AUTOSAR XML (schema 4-2-2)
package /STELLANTIS/EPT/ASWCs
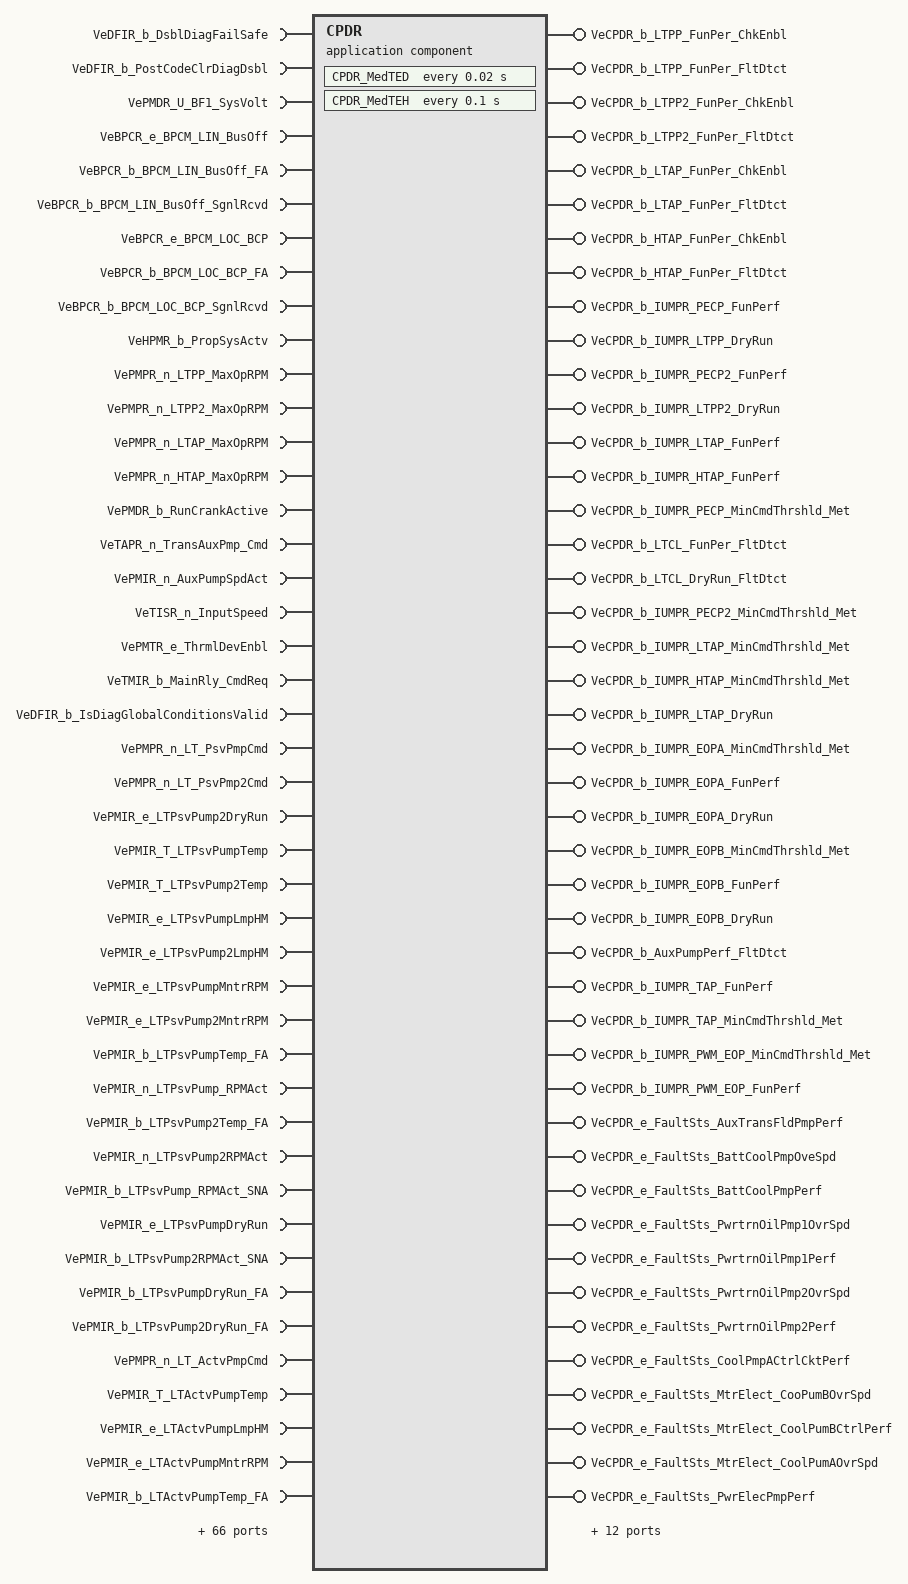
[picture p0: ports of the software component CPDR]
  application sw component type CPDR
    99 x require port:
      VeDFIR_b_DsblDiagFailSafe: variation-point={short-label=vpVeDFIR_b_DsblDiagFailSafe, sw-syscond=1}, nonqueued-receiver-com-spec{data-element=Value, init-value=0}, required-interface=VeDFIR_b_DsblDiagFailSafe
      VeDFIR_b_PostCodeClrDiagDsbl: variation-point={short-label=vpVeDFIR_b_PostCodeClrDiagDsbl, sw-syscond=1}, nonqueued-receiver-com-spec{data-element=Value, init-value=0}, required-interface=VeDFIR_b_PostCodeClrDiagDsbl
      VePMDR_U_BF1_SysVolt: variation-point={short-label=vpVePMDR_U_BF1_SysVolt, sw-syscond=1}, nonqueued-receiver-com-spec{data-element=Value, init-value=0}, required-interface=VePMDR_U_BF1_SysVolt
      VeBPCR_e_BPCM_LIN_BusOff: variation-point={short-label=vpVeBPCR_e_BPCM_LIN_BusOff, sw-syscond=1}, nonqueued-receiver-com-spec{data-element=Value, init-value=CeBPCR_e_LIN_BusOff_Disabled}, required-interface=VeBPCR_e_BPCM_LIN_BusOff
      VeBPCR_b_BPCM_LIN_BusOff_FA: variation-point={short-label=vpVeBPCR_b_BPCM_LIN_BusOff_FA, sw-syscond=1}, nonqueued-receiver-com-spec{data-element=Value, init-value=0}, required-interface=VeBPCR_b_BPCM_LIN_BusOff_FA
      VeBPCR_b_BPCM_LIN_BusOff_SgnlRcvd: variation-point={short-label=vpVeBPCR_b_BPCM_LIN_BusOff_SgnlRcvd, sw-syscond=1}, nonqueued-receiver-com-spec{data-element=Value, init-value=0}, required-interface=VeBPCR_b_BPCM_LIN_BusOff_SgnlRcvd
      VeBPCR_e_BPCM_LOC_BCP: variation-point={short-label=vpVeBPCR_e_BPCM_LOC_BCP, sw-syscond=1}, nonqueued-receiver-com-spec{data-element=Value, init-value=CeBPCR_e_LOC_BCP_False}, required-interface=VeBPCR_e_BPCM_LOC_BCP
      VeBPCR_b_BPCM_LOC_BCP_FA: variation-point={short-label=vpVeBPCR_b_BPCM_LOC_BCP_FA, sw-syscond=1}, nonqueued-receiver-com-spec{data-element=Value, init-value=0}, required-interface=VeBPCR_b_BPCM_LOC_BCP_FA
      VeBPCR_b_BPCM_LOC_BCP_SgnlRcvd: variation-point={short-label=vpVeBPCR_b_BPCM_LOC_BCP_SgnlRcvd, sw-syscond=1}, nonqueued-receiver-com-spec{data-element=Value, init-value=0}, required-interface=VeBPCR_b_BPCM_LOC_BCP_SgnlRcvd
      VeHPMR_b_PropSysActv: variation-point={short-label=vpVeHPMR_b_PropSysActv, sw-syscond=1}, nonqueued-receiver-com-spec{data-element=Value, init-value=0}, required-interface=VeHPMR_b_PropSysActv
      VePMPR_n_LTPP_MaxOpRPM: variation-point={short-label=vpVePMPR_n_LTPP_MaxOpRPM, sw-syscond=1}, nonqueued-receiver-com-spec{data-element=Value, init-value=0}, required-interface=VePMPR_n_LTPP_MaxOpRPM
      VePMPR_n_LTPP2_MaxOpRPM: variation-point={short-label=vpVePMPR_n_LTPP2_MaxOpRPM, sw-syscond=1}, nonqueued-receiver-com-spec{data-element=Value, init-value=0}, required-interface=VePMPR_n_LTPP2_MaxOpRPM
      VePMPR_n_LTAP_MaxOpRPM: variation-point={short-label=vpVePMPR_n_LTAP_MaxOpRPM, sw-syscond=1}, nonqueued-receiver-com-spec{data-element=Value, init-value=0}, required-interface=VePMPR_n_LTAP_MaxOpRPM
      VePMPR_n_HTAP_MaxOpRPM: variation-point={short-label=vpVePMPR_n_HTAP_MaxOpRPM, sw-syscond=1}, nonqueued-receiver-com-spec{data-element=Value, init-value=0}, required-interface=VePMPR_n_HTAP_MaxOpRPM
      VePMDR_b_RunCrankActive: variation-point={short-label=vpVePMDR_b_RunCrankActive, sw-syscond=1}, nonqueued-receiver-com-spec{data-element=Value, init-value=0}, required-interface=VePMDR_b_RunCrankActive
      VeTAPR_n_TransAuxPmp_Cmd: variation-point={short-label=vpVeTAPR_n_TransAuxPmp_Cmd, sw-syscond=1}, nonqueued-receiver-com-spec{data-element=Value, init-value=0}, required-interface=VeTAPR_n_TransAuxPmp_Cmd
      VePMIR_n_AuxPumpSpdAct: variation-point={short-label=vpVePMIR_n_AuxPumpSpdAct, sw-syscond=1}, nonqueued-receiver-com-spec{data-element=Value, init-value=0}, required-interface=VePMIR_n_AuxPumpSpdAct
      VeTISR_n_InputSpeed: variation-point={short-label=vpVeTISR_n_InputSpeed, sw-syscond=1}, nonqueued-receiver-com-spec{data-element=Value, init-value=0}, required-interface=VeTISR_n_InputSpeed
      VePMTR_e_ThrmlDevEnbl: variation-point={short-label=vpVePMTR_e_ThrmlDevEnbl, sw-syscond=1}, nonqueued-receiver-com-spec{data-element=Value, init-value=CePMTR_e_DISBL_All_Thrml}, required-interface=VePMTR_e_ThrmlDevEnbl
      VeTMIR_b_MainRly_CmdReq: variation-point={short-label=vpVeTMIR_b_MainRly_CmdReq, sw-syscond=1}, nonqueued-receiver-com-spec{data-element=Value, init-value=0}, required-interface=VeTMIR_b_MainRly_CmdReq
      VeDFIR_b_IsDiagGlobalConditionsValid: variation-point={short-label=vpVeDFIR_b_IsDiagGlobalConditionsValid, sw-syscond=1}, nonqueued-receiver-com-spec{data-element=Value, init-value=0}, required-interface=VeDFIR_b_IsDiagGlobalConditionsValid
      VePMPR_n_LT_PsvPmpCmd: variation-point={short-label=vpVePMPR_n_LT_PsvPmpCmd, sw-syscond=1}, nonqueued-receiver-com-spec{data-element=Value, init-value=0}, required-interface=VePMPR_n_LT_PsvPmpCmd
      VePMPR_n_LT_PsvPmp2Cmd: variation-point={short-label=vpVePMPR_n_LT_PsvPmp2Cmd, sw-syscond=1}, nonqueued-receiver-com-spec{data-element=Value, init-value=0}, required-interface=VePMPR_n_LT_PsvPmp2Cmd
      VePMIR_e_LTPsvPump2DryRun: variation-point={short-label=vpVePMIR_e_LTPsvPump2DryRun, sw-syscond=1}, nonqueued-receiver-com-spec{data-element=Value, init-value=CePMPR_e_FTSNA_False}, required-interface=VePMIR_e_LTPsvPump2DryRun
      VePMIR_T_LTPsvPumpTemp: variation-point={short-label=vpVePMIR_T_LTPsvPumpTemp, sw-syscond=1}, nonqueued-receiver-com-spec{data-element=Value, init-value=0}, required-interface=VePMIR_T_LTPsvPumpTemp
      VePMIR_T_LTPsvPump2Temp: variation-point={short-label=vpVePMIR_T_LTPsvPump2Temp, sw-syscond=1}, nonqueued-receiver-com-spec{data-element=Value, init-value=0}, required-interface=VePMIR_T_LTPsvPump2Temp
      VePMIR_e_LTPsvPumpLmpHM: variation-point={short-label=vpVePMIR_e_LTPsvPumpLmpHM, sw-syscond=1}, nonqueued-receiver-com-spec{data-element=Value, init-value=CePMPR_e_FTSNA_False}, required-interface=VePMIR_e_LTPsvPumpLmpHM
      VePMIR_e_LTPsvPump2LmpHM: variation-point={short-label=vpVePMIR_e_LTPsvPump2LmpHM, sw-syscond=1}, nonqueued-receiver-com-spec{data-element=Value, init-value=CePMPR_e_FTSNA_False}, required-interface=VePMIR_e_LTPsvPump2LmpHM
      VePMIR_e_LTPsvPumpMntrRPM: variation-point={short-label=vpVePMIR_e_LTPsvPumpMntrRPM, sw-syscond=1}, nonqueued-receiver-com-spec{data-element=Value, init-value=CePMPR_e_TFSNA_False}, required-interface=VePMIR_e_LTPsvPumpMntrRPM
      VePMIR_e_LTPsvPump2MntrRPM: variation-point={short-label=vpVePMIR_e_LTPsvPump2MntrRPM, sw-syscond=1}, nonqueued-receiver-com-spec{data-element=Value, init-value=CePMPR_e_TFSNA_False}, required-interface=VePMIR_e_LTPsvPump2MntrRPM
      VePMIR_b_LTPsvPumpTemp_FA: variation-point={short-label=vpVePMIR_b_LTPsvPumpTemp_FA, sw-syscond=1}, nonqueued-receiver-com-spec{data-element=Value, init-value=0}, required-interface=VePMIR_b_LTPsvPumpTemp_FA
      VePMIR_n_LTPsvPump_RPMAct: variation-point={short-label=vpVePMIR_n_LTPsvPump_RPMAct, sw-syscond=1}, nonqueued-receiver-com-spec{data-element=Value, init-value=0}, required-interface=VePMIR_n_LTPsvPump_RPMAct
      VePMIR_b_LTPsvPump2Temp_FA: variation-point={short-label=vpVePMIR_b_LTPsvPump2Temp_FA, sw-syscond=1}, nonqueued-receiver-com-spec{data-element=Value, init-value=0}, required-interface=VePMIR_b_LTPsvPump2Temp_FA
      VePMIR_n_LTPsvPump2RPMAct: variation-point={short-label=vpVePMIR_n_LTPsvPump2RPMAct, sw-syscond=1}, nonqueued-receiver-com-spec{data-element=Value, init-value=0}, required-interface=VePMIR_n_LTPsvPump2RPMAct
      VePMIR_b_LTPsvPump_RPMAct_SNA: variation-point={short-label=vpVePMIR_b_LTPsvPump_RPMAct_SNA, sw-syscond=1}, nonqueued-receiver-com-spec{data-element=Value, init-value=0}, required-interface=VePMIR_b_LTPsvPump_RPMAct_SNA
      VePMIR_e_LTPsvPumpDryRun: variation-point={short-label=vpVePMIR_e_LTPsvPumpDryRun, sw-syscond=1}, nonqueued-receiver-com-spec{data-element=Value, init-value=CePMPR_e_FTSNA_False}, required-interface=VePMIR_e_LTPsvPumpDryRun
      VePMIR_b_LTPsvPump2RPMAct_SNA: variation-point={short-label=vpVePMIR_b_LTPsvPump2RPMAct_SNA, sw-syscond=1}, nonqueued-receiver-com-spec{data-element=Value, init-value=0}, required-interface=VePMIR_b_LTPsvPump2RPMAct_SNA
      VePMIR_b_LTPsvPumpDryRun_FA: variation-point={short-label=vpVePMIR_b_LTPsvPumpDryRun_FA, sw-syscond=1}, nonqueued-receiver-com-spec{data-element=Value, init-value=0}, required-interface=VePMIR_b_LTPsvPumpDryRun_FA
      VePMIR_b_LTPsvPump2DryRun_FA: variation-point={short-label=vpVePMIR_b_LTPsvPump2DryRun_FA, sw-syscond=1}, nonqueued-receiver-com-spec{data-element=Value, init-value=0}, required-interface=VePMIR_b_LTPsvPump2DryRun_FA
      VePMPR_n_LT_ActvPmpCmd: variation-point={short-label=vpVePMPR_n_LT_ActvPmpCmd, sw-syscond=1}, nonqueued-receiver-com-spec{data-element=Value, init-value=0}, required-interface=VePMPR_n_LT_ActvPmpCmd
      VePMIR_T_LTActvPumpTemp: variation-point={short-label=vpVePMIR_T_LTActvPumpTemp, sw-syscond=1}, nonqueued-receiver-com-spec{data-element=Value, init-value=0}, required-interface=VePMIR_T_LTActvPumpTemp
      VePMIR_e_LTActvPumpLmpHM: variation-point={short-label=vpVePMIR_e_LTActvPumpLmpHM, sw-syscond=1}, nonqueued-receiver-com-spec{data-element=Value, init-value=CePMPR_e_FTSNA_False}, required-interface=VePMIR_e_LTActvPumpLmpHM
      VePMIR_e_LTActvPumpMntrRPM: variation-point={short-label=vpVePMIR_e_LTActvPumpMntrRPM, sw-syscond=1}, nonqueued-receiver-com-spec{data-element=Value, init-value=CePMPR_e_FTSNA_False}, required-interface=VePMIR_e_LTActvPumpMntrRPM
      VePMIR_b_LTActvPumpTemp_FA: variation-point={short-label=vpVePMIR_b_LTActvPumpTemp_FA, sw-syscond=1}, nonqueued-receiver-com-spec{data-element=Value, init-value=0}, required-interface=VePMIR_b_LTActvPumpTemp_FA
      VePMIR_n_LTActvPumpRPMAct: variation-point={short-label=vpVePMIR_n_LTActvPumpRPMAct, sw-syscond=1}, nonqueued-receiver-com-spec{data-element=Value, init-value=0}, required-interface=VePMIR_n_LTActvPumpRPMAct
      VePMIR_b_LTActvPumpRPMAct_SNA: variation-point={short-label=vpVePMIR_b_LTActvPumpRPMAct_SNA, sw-syscond=1}, nonqueued-receiver-com-spec{data-element=Value, init-value=0}, required-interface=VePMIR_b_LTActvPumpRPMAct_SNA
      VePMIR_b_LTActvPumpDryRun_SNA: variation-point={short-label=vpVePMIR_b_LTActvPumpDryRun_SNA, sw-syscond=1}, nonqueued-receiver-com-spec{data-element=Value, init-value=0}, required-interface=VePMIR_b_LTActvPumpDryRun_SNA
      VePMIR_e_LTActvPumpDryRun: variation-point={short-label=vpVePMIR_e_LTActvPumpDryRun, sw-syscond=1}, nonqueued-receiver-com-spec{data-element=Value, init-value=CePMPR_e_FTSNA_False}, required-interface=VePMIR_e_LTActvPumpDryRun
      VePMIR_b_LTActvPumpDryRun_FA: variation-point={short-label=vpVePMIR_b_LTActvPumpDryRun_FA, sw-syscond=1}, nonqueued-receiver-com-spec{data-element=Value, init-value=0}, required-interface=VePMIR_b_LTActvPumpDryRun_FA
      VePMIR_e_HTAuxPumpDryRun: variation-point={short-label=vpVePMIR_e_HTAuxPumpDryRun, sw-syscond=1}, nonqueued-receiver-com-spec{data-element=Value, init-value=CePMPR_e_FTSNA_False}, required-interface=VePMIR_e_HTAuxPumpDryRun
      VePMIR_n_HTAuxPumpRPMAct: variation-point={short-label=vpVePMIR_n_HTAuxPumpRPMAct, sw-syscond=1}, nonqueued-receiver-com-spec{data-element=Value, init-value=0}, required-interface=VePMIR_n_HTAuxPumpRPMAct
      VePMIR_b_HTAuxPumpRPMAct_SNA: variation-point={short-label=vpVePMIR_b_HTAuxPumpRPMAct_SNA, sw-syscond=1}, nonqueued-receiver-com-spec{data-element=Value, init-value=0}, required-interface=VePMIR_b_HTAuxPumpRPMAct_SNA
      VePMPR_n_HT_AuxPmpCmd: variation-point={short-label=vpVePMPR_n_HT_AuxPmpCmd, sw-syscond=1}, nonqueued-receiver-com-spec{data-element=Value, init-value=0}, required-interface=VePMPR_n_HT_AuxPmpCmd
      VePMIR_T_HTAuxPumpTemp: variation-point={short-label=vpVePMIR_T_HTAuxPumpTemp, sw-syscond=1}, nonqueued-receiver-com-spec{data-element=Value, init-value=0}, required-interface=VePMIR_T_HTAuxPumpTemp
      VePMIR_e_HTAuxPumpLmpHM: variation-point={short-label=vpVePMIR_e_HTAuxPumpLmpHM, sw-syscond=1}, nonqueued-receiver-com-spec{data-element=Value, init-value=CePMPR_e_FTSNA_False}, required-interface=VePMIR_e_HTAuxPumpLmpHM
      VePMIR_e_HTAuxPumpMntrRPM: variation-point={short-label=vpVePMIR_e_HTAuxPumpMntrRPM, sw-syscond=1}, nonqueued-receiver-com-spec{data-element=Value, init-value=CePMPR_e_TFSNA_False}, required-interface=VePMIR_e_HTAuxPumpMntrRPM
      VePMIR_b_HTAuxPumpTemp_FA: variation-point={short-label=vpVePMIR_b_HTAuxPumpTemp_FA, sw-syscond=1}, nonqueued-receiver-com-spec{data-element=Value, init-value=0}, required-interface=VePMIR_b_HTAuxPumpTemp_FA
      VePMIR_b_AuxPumpSpdAct_SNA: variation-point={short-label=vpVePMIR_b_AuxPumpSpdAct_SNA, sw-syscond=1}, nonqueued-receiver-com-spec{data-element=Value, init-value=0}, required-interface=VePMIR_b_AuxPumpSpdAct_SNA
      VePMIR_T_TransAuxPumpOilTemp: variation-point={short-label=vpVePMIR_T_TransAuxPumpOilTemp, sw-syscond=1}, nonqueued-receiver-com-spec{data-element=Value, init-value=0}, required-interface=VePMIR_T_TransAuxPumpOilTemp
      VePMIR_b_TransAuxPumpOilTemp_FA: variation-point={short-label=vpVePMIR_b_TransAuxPumpOilTemp_FA, sw-syscond=1}, nonqueued-receiver-com-spec{data-element=Value, init-value=0}, required-interface=VePMIR_b_TransAuxPumpOilTemp_FA
      VePMIR_b_TransAuxPumpDryRun_FA: variation-point={short-label=vpVePMIR_b_TransAuxPumpDryRun_FA, sw-syscond=1}, nonqueued-receiver-com-spec{data-element=Value, init-value=0}, required-interface=VePMIR_b_TransAuxPumpDryRun_FA
      VePMIR_b_AuxPumpSpdAct_FA: variation-point={short-label=vpVePMIR_b_AuxPumpSpdAct_FA, sw-syscond=1}, nonqueued-receiver-com-spec{data-element=Value, init-value=0}, required-interface=VePMIR_b_AuxPumpSpdAct_FA
      VePMIR_e_TransAuxPumpDryRun: variation-point={short-label=vpVePMIR_e_TransAuxPumpDryRun, sw-syscond=1}, nonqueued-receiver-com-spec{data-element=Value, init-value=CeTAPR_e_TAP_FalseTrueSNA_False}, required-interface=VePMIR_e_TransAuxPumpDryRun
      VeTAPR_n_TransAuxPmp2_Cmd: variation-point={short-label=vpVeTAPR_n_TransAuxPmp2_Cmd, sw-syscond=1}, nonqueued-receiver-com-spec{data-element=Value, init-value=0}, required-interface=VeTAPR_n_TransAuxPmp2_Cmd
      VePMIR_n_TransAuxPump2SpdAct: variation-point={short-label=vpVePMIR_n_TransAuxPump2SpdAct, sw-syscond=1}, nonqueued-receiver-com-spec{data-element=Value, init-value=0}, required-interface=VePMIR_n_TransAuxPump2SpdAct
      VePMIR_b_TransAuxPump2SpdAct_SNA: variation-point={short-label=vpVePMIR_b_TransAuxPump2SpdAct_SNA, sw-syscond=1}, nonqueued-receiver-com-spec{data-element=Value, init-value=0}, required-interface=VePMIR_b_TransAuxPump2SpdAct_SNA
      VePMIR_T_TransAuxPump2OilTemp: variation-point={short-label=vpVePMIR_T_TransAuxPump2OilTemp, sw-syscond=1}, nonqueued-receiver-com-spec{data-element=Value, init-value=0}, required-interface=VePMIR_T_TransAuxPump2OilTemp
      VePMIR_b_TransAuxPump2OilTemp_FA: variation-point={short-label=vpVePMIR_b_TransAuxPump2OilTemp_FA, sw-syscond=1}, nonqueued-receiver-com-spec{data-element=Value, init-value=0}, required-interface=VePMIR_b_TransAuxPump2OilTemp_FA
      VePMIR_b_TransAuxPump2DryRun_FA: variation-point={short-label=vpVePMIR_b_TransAuxPump2DryRun_FA, sw-syscond=1}, nonqueued-receiver-com-spec{data-element=Value, init-value=0}, required-interface=VePMIR_b_TransAuxPump2DryRun_FA
      VePMIR_b_TransAuxPump2SpdAct_FA: variation-point={short-label=vpVePMIR_b_TransAuxPump2SpdAct_FA, sw-syscond=1}, nonqueued-receiver-com-spec{data-element=Value, init-value=0}, required-interface=VePMIR_b_TransAuxPump2SpdAct_FA
      VePMIR_e_TransAuxPump2DryRun: variation-point={short-label=vpVePMIR_e_TransAuxPump2DryRun, sw-syscond=1}, nonqueued-receiver-com-spec{data-element=Value, init-value=CeTAPR_e_TAP_FalseTrueSNA_False}, required-interface=VePMIR_e_TransAuxPump2DryRun
      VeDMAB_y_StatusByte_LIN1_BusOff: nonqueued-receiver-com-spec{data-element=Value, init-value=0}, required-interface=VeDMAB_y_StatusByte_LIN1_BusOff
      VeDMAB_y_StatusByte_LostCommTAP: nonqueued-receiver-com-spec{data-element=Value, init-value=0}, required-interface=VeDMAB_y_StatusByte_LostCommTAP
      VeDMAB_y_StatusByte_ThrmlRlyCtrlCkt: nonqueued-receiver-com-spec{data-element=Value, init-value=0}, required-interface=VeDMAB_y_StatusByte_ThrmlRlyCtrlCkt
      VeDMAB_y_StatusByte_LostCommHB_CoolPmp: nonqueued-receiver-com-spec{data-element=Value, init-value=0}, required-interface=VeDMAB_y_StatusByte_LostCommHB_CoolPmp
      VeDMAB_y_StatusByte_CommBus_B_Off: nonqueued-receiver-com-spec{data-element=Value, init-value=0}, required-interface=VeDMAB_y_StatusByte_CommBus_B_Off
      VeDMAB_y_StatusByte_InvData_BECM_CANC11: nonqueued-receiver-com-spec{data-element=Value, init-value=0}, required-interface=VeDMAB_y_StatusByte_InvData_BECM_CANC11
      VeDMAB_y_StatusByte_LosCommBECM_A_CANC11: nonqueued-receiver-com-spec{data-element=Value, init-value=0}, required-interface=VeDMAB_y_StatusByte_LosCommBECM_A_CANC11
      VeDMAB_y_StatusByte_CommBusOff: nonqueued-receiver-com-spec{data-element=Value, init-value=0}, required-interface=VeDMAB_y_StatusByte_CommBusOff
      VeDMAB_y_StatusByte_InvData_BECM: nonqueued-receiver-com-spec{data-element=Value, init-value=0}, required-interface=VeDMAB_y_StatusByte_InvData_BECM
      VeDMAB_y_StatusByte_LosCommBECM_A: nonqueued-receiver-com-spec{data-element=Value, init-value=0}, required-interface=VeDMAB_y_StatusByte_LosCommBECM_A
      VeDMAB_y_StatusByte_BattCoolPmpPerf: nonqueued-receiver-com-spec{data-element=Value, init-value=0}, required-interface=VeDMAB_y_StatusByte_BattCoolPmpPerf
      VeDMAB_y_StatusByte_BattCoolPmpOveSpd: nonqueued-receiver-com-spec{data-element=Value, init-value=0}, required-interface=VeDMAB_y_StatusByte_BattCoolPmpOveSpd
      VeDMAB_y_StatusByte_LostCommPwrtrn_OilPmp1: nonqueued-receiver-com-spec{data-element=Value, init-value=0}, required-interface=VeDMAB_y_StatusByte_LostCommPwrtrn_OilPmp1
      VeDMAB_y_StatusByte_PwrtrnOilPmp1OvrSpd: nonqueued-receiver-com-spec{data-element=Value, init-value=0}, required-interface=VeDMAB_y_StatusByte_PwrtrnOilPmp1OvrSpd
      VeDMAB_y_StatusByte_PwrtrnOilPmp1Perf: nonqueued-receiver-com-spec{data-element=Value, init-value=0}, required-interface=VeDMAB_y_StatusByte_PwrtrnOilPmp1Perf
      VeDMAB_y_StatusByte_LIN3_BusOff: nonqueued-receiver-com-spec{data-element=Value, init-value=0}, required-interface=VeDMAB_y_StatusByte_LIN3_BusOff
      VeDMAB_y_StatusByte_LostCommPwrtrn_OilPmp2: nonqueued-receiver-com-spec{data-element=Value, init-value=0}, required-interface=VeDMAB_y_StatusByte_LostCommPwrtrn_OilPmp2
      VeDMAB_y_StatusByte_PwrtrnOilPmp2OvrSpd: nonqueued-receiver-com-spec{data-element=Value, init-value=0}, required-interface=VeDMAB_y_StatusByte_PwrtrnOilPmp2OvrSpd
      VeDMAB_y_StatusByte_PwrtrnOilPmp2Perf: nonqueued-receiver-com-spec{data-element=Value, init-value=0}, required-interface=VeDMAB_y_StatusByte_PwrtrnOilPmp2Perf
      VeDMAB_y_StatusByte_LIN2_BusOff: nonqueued-receiver-com-spec{data-element=Value, init-value=0}, required-interface=VeDMAB_y_StatusByte_LIN2_BusOff
      VeDMAB_y_StatusByte_LostCommCoolPmpA: nonqueued-receiver-com-spec{data-element=Value, init-value=0}, required-interface=VeDMAB_y_StatusByte_LostCommCoolPmpA
      VeDMAB_y_StatusByte_CoolPmpACtrlCktPerf: nonqueued-receiver-com-spec{data-element=Value, init-value=0}, required-interface=VeDMAB_y_StatusByte_CoolPmpACtrlCktPerf
      VeDMAB_y_StatusByte_LostCommMtrElectCoolPmpB: nonqueued-receiver-com-spec{data-element=Value, init-value=0}, required-interface=VeDMAB_y_StatusByte_LostCommMtrElectCoolPmpB
      VeDMAB_y_StatusByte_MtrElect_CoolPumBCtrlPerf: nonqueued-receiver-com-spec{data-element=Value, init-value=0}, required-interface=VeDMAB_y_StatusByte_MtrElect_CoolPumBCtrlPerf
      VeDMAB_y_StatusByte_LostCommMtrElectCoolPmpA: nonqueued-receiver-com-spec{data-element=Value, init-value=0}, required-interface=VeDMAB_y_StatusByte_LostCommMtrElectCoolPmpA
      VeDMAB_y_StatusByte_MtrElect_CoolPumAOvrSpd: nonqueued-receiver-com-spec{data-element=Value, init-value=0}, required-interface=VeDMAB_y_StatusByte_MtrElect_CoolPumAOvrSpd
      VeDMAB_y_StatusByte_PwrElecPmpPerf: nonqueued-receiver-com-spec{data-element=Value, init-value=0}, required-interface=VeDMAB_y_StatusByte_PwrElecPmpPerf
      VeDMAB_y_StatusByte_MtrElect_CooPumBOvrSpd: nonqueued-receiver-com-spec{data-element=Value, init-value=0}, required-interface=VeDMAB_y_StatusByte_MtrElect_CooPumBOvrSpd
    45 x provide port:
      VeCPDR_b_LTPP_FunPer_ChkEnbl: nonqueued-sender-com-spec{data-element=Value, init-value=0}, provided-interface=VeCPDR_b_LTPP_FunPer_ChkEnbl
      VeCPDR_b_LTPP_FunPer_FltDtct: nonqueued-sender-com-spec{data-element=Value, init-value=0}, provided-interface=VeCPDR_b_LTPP_FunPer_FltDtct
      VeCPDR_b_LTPP2_FunPer_ChkEnbl: nonqueued-sender-com-spec{data-element=Value, init-value=0}, provided-interface=VeCPDR_b_LTPP2_FunPer_ChkEnbl
      VeCPDR_b_LTPP2_FunPer_FltDtct: nonqueued-sender-com-spec{data-element=Value, init-value=0}, provided-interface=VeCPDR_b_LTPP2_FunPer_FltDtct
      VeCPDR_b_LTAP_FunPer_ChkEnbl: nonqueued-sender-com-spec{data-element=Value, init-value=0}, provided-interface=VeCPDR_b_LTAP_FunPer_ChkEnbl
      VeCPDR_b_LTAP_FunPer_FltDtct: nonqueued-sender-com-spec{data-element=Value, init-value=0}, provided-interface=VeCPDR_b_LTAP_FunPer_FltDtct
      VeCPDR_b_HTAP_FunPer_ChkEnbl: nonqueued-sender-com-spec{data-element=Value, init-value=0}, provided-interface=VeCPDR_b_HTAP_FunPer_ChkEnbl
      VeCPDR_b_HTAP_FunPer_FltDtct: nonqueued-sender-com-spec{data-element=Value, init-value=0}, provided-interface=VeCPDR_b_HTAP_FunPer_FltDtct
      VeCPDR_b_IUMPR_PECP_FunPerf: nonqueued-sender-com-spec{data-element=Value, init-value=0}, provided-interface=VeCPDR_b_IUMPR_PECP_FunPerf
      VeCPDR_b_IUMPR_LTPP_DryRun: nonqueued-sender-com-spec{data-element=Value, init-value=0}, provided-interface=VeCPDR_b_IUMPR_LTPP_DryRun
      VeCPDR_b_IUMPR_PECP2_FunPerf: nonqueued-sender-com-spec{data-element=Value, init-value=0}, provided-interface=VeCPDR_b_IUMPR_PECP2_FunPerf
      VeCPDR_b_IUMPR_LTPP2_DryRun: nonqueued-sender-com-spec{data-element=Value, init-value=0}, provided-interface=VeCPDR_b_IUMPR_LTPP2_DryRun
      VeCPDR_b_IUMPR_LTAP_FunPerf: nonqueued-sender-com-spec{data-element=Value, init-value=0}, provided-interface=VeCPDR_b_IUMPR_LTAP_FunPerf
      VeCPDR_b_IUMPR_HTAP_FunPerf: nonqueued-sender-com-spec{data-element=Value, init-value=0}, provided-interface=VeCPDR_b_IUMPR_HTAP_FunPerf
      VeCPDR_b_IUMPR_PECP_MinCmdThrshld_Met: nonqueued-sender-com-spec{data-element=Value, init-value=0}, provided-interface=VeCPDR_b_IUMPR_PECP_MinCmdThrshld_Met
      VeCPDR_b_LTCL_FunPer_FltDtct: nonqueued-sender-com-spec{data-element=Value, init-value=0}, provided-interface=VeCPDR_b_LTCL_FunPer_FltDtct
      VeCPDR_b_LTCL_DryRun_FltDtct: nonqueued-sender-com-spec{data-element=Value, init-value=0}, provided-interface=VeCPDR_b_LTCL_DryRun_FltDtct
      VeCPDR_b_IUMPR_PECP2_MinCmdThrshld_Met: nonqueued-sender-com-spec{data-element=Value, init-value=0}, provided-interface=VeCPDR_b_IUMPR_PECP2_MinCmdThrshld_Met
      VeCPDR_b_IUMPR_LTAP_MinCmdThrshld_Met: nonqueued-sender-com-spec{data-element=Value, init-value=0}, provided-interface=VeCPDR_b_IUMPR_LTAP_MinCmdThrshld_Met
      VeCPDR_b_IUMPR_HTAP_MinCmdThrshld_Met: nonqueued-sender-com-spec{data-element=Value, init-value=0}, provided-interface=VeCPDR_b_IUMPR_HTAP_MinCmdThrshld_Met
      VeCPDR_b_IUMPR_LTAP_DryRun: nonqueued-sender-com-spec{data-element=Value, init-value=0}, provided-interface=VeCPDR_b_IUMPR_LTAP_DryRun
      VeCPDR_b_IUMPR_EOPA_MinCmdThrshld_Met: nonqueued-sender-com-spec{data-element=Value, init-value=0}, provided-interface=VeCPDR_b_IUMPR_EOPA_MinCmdThrshld_Met
      VeCPDR_b_IUMPR_EOPA_FunPerf: nonqueued-sender-com-spec{data-element=Value, init-value=0}, provided-interface=VeCPDR_b_IUMPR_EOPA_FunPerf
      VeCPDR_b_IUMPR_EOPA_DryRun: nonqueued-sender-com-spec{data-element=Value, init-value=0}, provided-interface=VeCPDR_b_IUMPR_EOPA_DryRun
      VeCPDR_b_IUMPR_EOPB_MinCmdThrshld_Met: nonqueued-sender-com-spec{data-element=Value, init-value=0}, provided-interface=VeCPDR_b_IUMPR_EOPB_MinCmdThrshld_Met
      VeCPDR_b_IUMPR_EOPB_FunPerf: nonqueued-sender-com-spec{data-element=Value, init-value=0}, provided-interface=VeCPDR_b_IUMPR_EOPB_FunPerf
      VeCPDR_b_IUMPR_EOPB_DryRun: nonqueued-sender-com-spec{data-element=Value, init-value=0}, provided-interface=VeCPDR_b_IUMPR_EOPB_DryRun
      VeCPDR_b_AuxPumpPerf_FltDtct: nonqueued-sender-com-spec{data-element=Value, init-value=0}, provided-interface=VeCPDR_b_AuxPumpPerf_FltDtct
      VeCPDR_b_IUMPR_TAP_FunPerf: nonqueued-sender-com-spec{data-element=Value, init-value=0}, provided-interface=VeCPDR_b_IUMPR_TAP_FunPerf
      VeCPDR_b_IUMPR_TAP_MinCmdThrshld_Met: nonqueued-sender-com-spec{data-element=Value, init-value=0}, provided-interface=VeCPDR_b_IUMPR_TAP_MinCmdThrshld_Met
      VeCPDR_b_IUMPR_PWM_EOP_MinCmdThrshld_Met: nonqueued-sender-com-spec{data-element=Value, init-value=0}, provided-interface=VeCPDR_b_IUMPR_PWM_EOP_MinCmdThrshld_Met
      VeCPDR_b_IUMPR_PWM_EOP_FunPerf: nonqueued-sender-com-spec{data-element=Value, init-value=0}, provided-interface=VeCPDR_b_IUMPR_PWM_EOP_FunPerf
      VeCPDR_e_FaultSts_AuxTransFldPmpPerf: nonqueued-sender-com-spec{data-element=Value, init-value=CeDFIB_e_Init}, provided-interface=VeCPDR_e_FaultSts_AuxTransFldPmpPerf
      VeCPDR_e_FaultSts_BattCoolPmpOveSpd: nonqueued-sender-com-spec{data-element=Value, init-value=CeDFIB_e_Init}, provided-interface=VeCPDR_e_FaultSts_BattCoolPmpOveSpd
      VeCPDR_e_FaultSts_BattCoolPmpPerf: nonqueued-sender-com-spec{data-element=Value, init-value=CeDFIB_e_Init}, provided-interface=VeCPDR_e_FaultSts_BattCoolPmpPerf
      VeCPDR_e_FaultSts_PwrtrnOilPmp1OvrSpd: nonqueued-sender-com-spec{data-element=Value, init-value=CeDFIB_e_Init}, provided-interface=VeCPDR_e_FaultSts_PwrtrnOilPmp1OvrSpd
      VeCPDR_e_FaultSts_PwrtrnOilPmp1Perf: nonqueued-sender-com-spec{data-element=Value, init-value=CeDFIB_e_Init}, provided-interface=VeCPDR_e_FaultSts_PwrtrnOilPmp1Perf
      VeCPDR_e_FaultSts_PwrtrnOilPmp2OvrSpd: nonqueued-sender-com-spec{data-element=Value, init-value=CeDFIB_e_Init}, provided-interface=VeCPDR_e_FaultSts_PwrtrnOilPmp2OvrSpd
      VeCPDR_e_FaultSts_PwrtrnOilPmp2Perf: nonqueued-sender-com-spec{data-element=Value, init-value=CeDFIB_e_Init}, provided-interface=VeCPDR_e_FaultSts_PwrtrnOilPmp2Perf
      VeCPDR_e_FaultSts_CoolPmpACtrlCktPerf: nonqueued-sender-com-spec{data-element=Value, init-value=CeDFIB_e_Init}, provided-interface=VeCPDR_e_FaultSts_CoolPmpACtrlCktPerf
      VeCPDR_e_FaultSts_MtrElect_CooPumBOvrSpd: nonqueued-sender-com-spec{data-element=Value, init-value=CeDFIB_e_Init}, provided-interface=VeCPDR_e_FaultSts_MtrElect_CooPumBOvrSpd
      VeCPDR_e_FaultSts_MtrElect_CoolPumBCtrlPerf: nonqueued-sender-com-spec{data-element=Value, init-value=CeDFIB_e_Init}, provided-interface=VeCPDR_e_FaultSts_MtrElect_CoolPumBCtrlPerf
      VeCPDR_e_FaultSts_MtrElect_CoolPumAOvrSpd: nonqueued-sender-com-spec{data-element=Value, init-value=CeDFIB_e_Init}, provided-interface=VeCPDR_e_FaultSts_MtrElect_CoolPumAOvrSpd
      VeCPDR_e_FaultSts_PwrElecPmpPerf: nonqueued-sender-com-spec{data-element=Value, init-value=CeDFIB_e_Init}, provided-interface=VeCPDR_e_FaultSts_PwrElecPmpPerf
      VeCPDR_e_FaultSts_Aux_TF_Pmp_CM_Fdbck_SigRan: nonqueued-sender-com-spec{data-element=Value, init-value=CeDFIB_e_Init}, provided-interface=VeCPDR_e_FaultSts_Aux_TF_Pmp_CM_Fdbck_SigRan
    11 x require port:
      NeCPDR_Cnt_EOPA_FunDryRun_MFOP_Rx: nv-require-com-spec{init-value=0, variable=NeCPDR_Cnt_EOPA_FunDryRun_MFOP}, required-interface=NeCPDR_Cnt_EOPA_FunDryRun_MFOP
      NeCPDR_Cnt_EOPA_FunPer_MFOP_Rx: nv-require-com-spec{init-value=0, variable=NeCPDR_Cnt_EOPA_FunPer_MFOP}, required-interface=NeCPDR_Cnt_EOPA_FunPer_MFOP
      NeCPDR_Cnt_EOPB_FunDryRun_MFOP_Rx: nv-require-com-spec{init-value=0, variable=NeCPDR_Cnt_EOPB_FunDryRun_MFOP}, required-interface=NeCPDR_Cnt_EOPB_FunDryRun_MFOP
      NeCPDR_Cnt_EOPB_FunPer_MFOP_Rx: nv-require-com-spec{init-value=0, variable=NeCPDR_Cnt_EOPB_FunPer_MFOP}, required-interface=NeCPDR_Cnt_EOPB_FunPer_MFOP
      NeCPDR_Cnt_HTAP_FunPer_MFOP_Rx: nv-require-com-spec{init-value=0, variable=NeCPDR_Cnt_HTAP_FunPer_MFOP}, required-interface=NeCPDR_Cnt_HTAP_FunPer_MFOP
      NeCPDR_Cnt_LTAP_FunDryRun_MFOP_Rx: nv-require-com-spec{init-value=0, variable=NeCPDR_Cnt_LTAP_FunDryRun_MFOP}, required-interface=NeCPDR_Cnt_LTAP_FunDryRun_MFOP
      NeCPDR_Cnt_LTAP_FunPer_MFOP_Rx: nv-require-com-spec{init-value=0, variable=NeCPDR_Cnt_LTAP_FunPer_MFOP}, required-interface=NeCPDR_Cnt_LTAP_FunPer_MFOP
      NeCPDR_Cnt_LTPP2_FunDryRun_MFOP_Rx: nv-require-com-spec{init-value=0, variable=NeCPDR_Cnt_LTPP2_FunDryRun_MFOP}, required-interface=NeCPDR_Cnt_LTPP2_FunDryRun_MFOP
      NeCPDR_Cnt_LTPP2_FunPer_MFOP_Rx: nv-require-com-spec{init-value=0, variable=NeCPDR_Cnt_LTPP2_FunPer_MFOP}, required-interface=NeCPDR_Cnt_LTPP2_FunPer_MFOP
      NeCPDR_Cnt_LTPP_FunDryRun_MFOP_Rx: nv-require-com-spec{init-value=0, variable=NeCPDR_Cnt_LTPP_FunDryRun_MFOP}, required-interface=NeCPDR_Cnt_LTPP_FunDryRun_MFOP
      NeCPDR_Cnt_LTPP_FunPer_MFOP_Rx: nv-require-com-spec{init-value=0, variable=NeCPDR_Cnt_LTPP_FunPer_MFOP}, required-interface=NeCPDR_Cnt_LTPP_FunPer_MFOP
    11 x provide port:
      NeCPDR_Cnt_EOPA_FunDryRun_MFOP: nv-provide-com-spec{ram-block-init-value=0, variable=NeCPDR_Cnt_EOPA_FunDryRun_MFOP}, provided-interface=NeCPDR_Cnt_EOPA_FunDryRun_MFOP
      NeCPDR_Cnt_EOPA_FunPer_MFOP: nv-provide-com-spec{ram-block-init-value=0, variable=NeCPDR_Cnt_EOPA_FunPer_MFOP}, provided-interface=NeCPDR_Cnt_EOPA_FunPer_MFOP
      NeCPDR_Cnt_EOPB_FunDryRun_MFOP: nv-provide-com-spec{ram-block-init-value=0, variable=NeCPDR_Cnt_EOPB_FunDryRun_MFOP}, provided-interface=NeCPDR_Cnt_EOPB_FunDryRun_MFOP
      NeCPDR_Cnt_EOPB_FunPer_MFOP: nv-provide-com-spec{ram-block-init-value=0, variable=NeCPDR_Cnt_EOPB_FunPer_MFOP}, provided-interface=NeCPDR_Cnt_EOPB_FunPer_MFOP
      NeCPDR_Cnt_HTAP_FunPer_MFOP: nv-provide-com-spec{ram-block-init-value=0, variable=NeCPDR_Cnt_HTAP_FunPer_MFOP}, provided-interface=NeCPDR_Cnt_HTAP_FunPer_MFOP
      NeCPDR_Cnt_LTAP_FunDryRun_MFOP: nv-provide-com-spec{ram-block-init-value=0, variable=NeCPDR_Cnt_LTAP_FunDryRun_MFOP}, provided-interface=NeCPDR_Cnt_LTAP_FunDryRun_MFOP
      NeCPDR_Cnt_LTAP_FunPer_MFOP: nv-provide-com-spec{ram-block-init-value=0, variable=NeCPDR_Cnt_LTAP_FunPer_MFOP}, provided-interface=NeCPDR_Cnt_LTAP_FunPer_MFOP
      NeCPDR_Cnt_LTPP2_FunDryRun_MFOP: nv-provide-com-spec{ram-block-init-value=0, variable=NeCPDR_Cnt_LTPP2_FunDryRun_MFOP}, provided-interface=NeCPDR_Cnt_LTPP2_FunDryRun_MFOP
      NeCPDR_Cnt_LTPP2_FunPer_MFOP: nv-provide-com-spec{ram-block-init-value=0, variable=NeCPDR_Cnt_LTPP2_FunPer_MFOP}, provided-interface=NeCPDR_Cnt_LTPP2_FunPer_MFOP
      NeCPDR_Cnt_LTPP_FunDryRun_MFOP: nv-provide-com-spec{ram-block-init-value=0, variable=NeCPDR_Cnt_LTPP_FunDryRun_MFOP}, provided-interface=NeCPDR_Cnt_LTPP_FunDryRun_MFOP
      NeCPDR_Cnt_LTPP_FunPer_MFOP: nv-provide-com-spec{ram-block-init-value=0, variable=NeCPDR_Cnt_LTPP_FunPer_MFOP}, provided-interface=NeCPDR_Cnt_LTPP_FunPer_MFOP
    behavior IB_CPDR: data-type-mapping=msADTtoIDTMapping, handle-termination-and-restart=NO-SUPPORT
      timing event Event_MedTED: start-on-event=CPDR_MedTED, period=0.02
      timing event Event_MedTEH: start-on-event=CPDR_MedTEH, period=0.1
      init event Event_CPDR_ac_Init: start-on-event=CPDR_ac_Init
      init event Event_PwrOn: start-on-event=CPDR_PwrOn
      init event Event_PwrOff: start-on-event=CPDR_PwrOff
      explicit-inter-runnable-variables:
        16 x data, all with category=VALUE, sw-calibration-access=READ-ONLY:
          BF1_SysVolt_AD_IRV: type=Float, init-value=0
          DsblDiagFailSafe_AD_write_IRV: type=Boolean, init-value=0
          PostCodeClrDiagDsbl_AD_write_IRV: type=Boolean, init-value=0
          PropSysActv_AD_write_IRV: type=Boolean, init-value=0
          LTPP_MaxOpRPM_AD_write_IRV: type=Float, init-value=0
          LTPP2_MaxOpRPM_AD_write_IRV: type=Float, init-value=0
          BPCM_LIN_BusOff_AD_write_IRV: type=TeBPCR_e_LIN_BusOff, init-value=CeBPCR_e_LIN_BusOff_Disabled
          BPCM_LIN_BusOff_FA_AD_write_IRV: type=Boolean, init-value=0
          BPCM_LIN_BusOff_SgnlRcvd_AD_write_IRV: type=Boolean, init-value=0
          BPCM_LOC_BCP_AD_write_IRV: type=TeBPCR_e_LOC_BCP, init-value=CeBPCR_e_LOC_BCP_False
          BPCM_LOC_BCP_FA_AD_write_IRV: type=Boolean, init-value=0
          BPCM_LOC_BCP_SgnlRcvd_AD_write_IRV: type=Boolean, init-value=0
          LTAP_MaxOpRPM_AD_write_IRV: type=Float, init-value=0
          HTAP_MaxOpRPM_AD_write_IRV: type=Float, init-value=0
          TransAuxPmp_Cmd_AD_write_IRV: type=Float, init-value=0
          AuxPumpSpdAct_AD_write_IRV: type=Float, init-value=0
      5 x runnable:
        CPDR_ac_Init
          data-send-points:
            13 x access:
              OUT_VeCPDR_e_FaultSts_AuxTransFldPmpPerf_Value: accessed-variable=VeCPDR_e_FaultSts_AuxTransFldPmpPerf.Value
              OUT_VeCPDR_e_FaultSts_BattCoolPmpOveSpd_Value: accessed-variable=VeCPDR_e_FaultSts_BattCoolPmpOveSpd.Value
              OUT_VeCPDR_e_FaultSts_BattCoolPmpPerf_Value: accessed-variable=VeCPDR_e_FaultSts_BattCoolPmpPerf.Value
              OUT_VeCPDR_e_FaultSts_PwrtrnOilPmp1OvrSpd_Value: accessed-variable=VeCPDR_e_FaultSts_PwrtrnOilPmp1OvrSpd.Value
              OUT_VeCPDR_e_FaultSts_PwrtrnOilPmp1Perf_Value: accessed-variable=VeCPDR_e_FaultSts_PwrtrnOilPmp1Perf.Value
              OUT_VeCPDR_e_FaultSts_PwrtrnOilPmp2OvrSpd_Value: accessed-variable=VeCPDR_e_FaultSts_PwrtrnOilPmp2OvrSpd.Value
              OUT_VeCPDR_e_FaultSts_PwrtrnOilPmp2Perf_Value: accessed-variable=VeCPDR_e_FaultSts_PwrtrnOilPmp2Perf.Value
              OUT_VeCPDR_e_FaultSts_CoolPmpACtrlCktPerf_Value: accessed-variable=VeCPDR_e_FaultSts_CoolPmpACtrlCktPerf.Value
              OUT_VeCPDR_e_FaultSts_MtrElect_CooPumBOvrSpd_Value: accessed-variable=VeCPDR_e_FaultSts_MtrElect_CooPumBOvrSpd.Value
              OUT_VeCPDR_e_FaultSts_MtrElect_CoolPumBCtrlPerf_Value: accessed-variable=VeCPDR_e_FaultSts_MtrElect_CoolPumBCtrlPerf.Value
              OUT_VeCPDR_e_FaultSts_MtrElect_CoolPumAOvrSpd_Value: accessed-variable=VeCPDR_e_FaultSts_MtrElect_CoolPumAOvrSpd.Value
              OUT_VeCPDR_e_FaultSts_PwrElecPmpPerf_Value: accessed-variable=VeCPDR_e_FaultSts_PwrElecPmpPerf.Value
              OUT_VeCPDR_e_FaultSts_Aux_TF_Pmp_CM_Fdbck_SigRan_Value: accessed-variable=VeCPDR_e_FaultSts_Aux_TF_Pmp_CM_Fdbck_SigRan.Value
        CPDR_MedTED
          data-receive-point-by-arguments:
            22 x access:
              IN_VeBPCR_b_BPCM_LIN_BusOff_FA_Value: accessed-variable=VeBPCR_b_BPCM_LIN_BusOff_FA.Value, variation-point={short-label=vpIN_VeBPCR_b_BPCM_LIN_BusOff_FA_Value, sw-syscond=1}
              IN_VeBPCR_b_BPCM_LIN_BusOff_SgnlRcvd_Value: accessed-variable=VeBPCR_b_BPCM_LIN_BusOff_SgnlRcvd.Value, variation-point={short-label=vpIN_VeBPCR_b_BPCM_LIN_BusOff_SgnlRcvd_Value, sw-syscond=1}
              IN_VeBPCR_b_BPCM_LOC_BCP_FA_Value: accessed-variable=VeBPCR_b_BPCM_LOC_BCP_FA.Value, variation-point={short-label=vpIN_VeBPCR_b_BPCM_LOC_BCP_FA_Value, sw-syscond=1}
              IN_VeBPCR_b_BPCM_LOC_BCP_SgnlRcvd_Value: accessed-variable=VeBPCR_b_BPCM_LOC_BCP_SgnlRcvd.Value, variation-point={short-label=vpIN_VeBPCR_b_BPCM_LOC_BCP_SgnlRcvd_Value, sw-syscond=1}
              IN_VeBPCR_e_BPCM_LIN_BusOff_Value: accessed-variable=VeBPCR_e_BPCM_LIN_BusOff.Value, variation-point={short-label=vpIN_VeBPCR_e_BPCM_LIN_BusOff_Value, sw-syscond=1}
              IN_VeBPCR_e_BPCM_LOC_BCP_Value: accessed-variable=VeBPCR_e_BPCM_LOC_BCP.Value, variation-point={short-label=vpIN_VeBPCR_e_BPCM_LOC_BCP_Value, sw-syscond=1}
              IN_VeDFIR_b_DsblDiagFailSafe_Value: accessed-variable=VeDFIR_b_DsblDiagFailSafe.Value, variation-point={short-label=vpIN_VeDFIR_b_DsblDiagFailSafe_Value, sw-syscond=1}
              IN_VeDFIR_b_PostCodeClrDiagDsbl_Value: accessed-variable=VeDFIR_b_PostCodeClrDiagDsbl.Value, variation-point={short-label=vpIN_VeDFIR_b_PostCodeClrDiagDsbl_Value, sw-syscond=1}
              IN_VeDMAB_y_StatusByte_LIN1_BusOff_Value: accessed-variable=VeDMAB_y_StatusByte_LIN1_BusOff.Value
              IN_VeDMAB_y_StatusByte_LostCommTAP_Value: accessed-variable=VeDMAB_y_StatusByte_LostCommTAP.Value
              IN_VeDMAB_y_StatusByte_ThrmlRlyCtrlCkt_Value: accessed-variable=VeDMAB_y_StatusByte_ThrmlRlyCtrlCkt.Value
              IN_VeHPMR_b_PropSysActv_Value: accessed-variable=VeHPMR_b_PropSysActv.Value, variation-point={short-label=vpIN_VeHPMR_b_PropSysActv_Value, sw-syscond=1}
              IN_VePMDR_U_BF1_SysVolt_Value: accessed-variable=VePMDR_U_BF1_SysVolt.Value, variation-point={short-label=vpIN_VePMDR_U_BF1_SysVolt_Value, sw-syscond=1}
              IN_VePMDR_b_RunCrankActive_Value: accessed-variable=VePMDR_b_RunCrankActive.Value, variation-point={short-label=vpIN_VePMDR_b_RunCrankActive_Value, sw-syscond=1}
              IN_VePMIR_n_AuxPumpSpdAct_Value: accessed-variable=VePMIR_n_AuxPumpSpdAct.Value, variation-point={short-label=vpIN_VePMIR_n_AuxPumpSpdAct_Value, sw-syscond=1}
              IN_VePMPR_n_HTAP_MaxOpRPM_Value: accessed-variable=VePMPR_n_HTAP_MaxOpRPM.Value, variation-point={short-label=vpIN_VePMPR_n_HTAP_MaxOpRPM_Value, sw-syscond=1}
              IN_VePMPR_n_LTAP_MaxOpRPM_Value: accessed-variable=VePMPR_n_LTAP_MaxOpRPM.Value, variation-point={short-label=vpIN_VePMPR_n_LTAP_MaxOpRPM_Value, sw-syscond=1}
              IN_VePMPR_n_LTPP2_MaxOpRPM_Value: accessed-variable=VePMPR_n_LTPP2_MaxOpRPM.Value, variation-point={short-label=vpIN_VePMPR_n_LTPP2_MaxOpRPM_Value, sw-syscond=1}
              IN_VePMPR_n_LTPP_MaxOpRPM_Value: accessed-variable=VePMPR_n_LTPP_MaxOpRPM.Value, variation-point={short-label=vpIN_VePMPR_n_LTPP_MaxOpRPM_Value, sw-syscond=1}
              IN_VePMTR_e_ThrmlDevEnbl_Value: accessed-variable=VePMTR_e_ThrmlDevEnbl.Value, variation-point={short-label=vpIN_VePMTR_e_ThrmlDevEnbl_Value, sw-syscond=1}
              IN_VeTAPR_n_TransAuxPmp_Cmd_Value: accessed-variable=VeTAPR_n_TransAuxPmp_Cmd.Value, variation-point={short-label=vpIN_VeTAPR_n_TransAuxPmp_Cmd_Value, sw-syscond=1}
              IN_VeTISR_n_InputSpeed_Value: accessed-variable=VeTISR_n_InputSpeed.Value, variation-point={short-label=vpIN_VeTISR_n_InputSpeed_Value, sw-syscond=1}
          data-send-points:
            4 x access:
              OUT_VeCPDR_b_AuxPumpPerf_FltDtct_Value: accessed-variable=VeCPDR_b_AuxPumpPerf_FltDtct.Value
              OUT_VeCPDR_b_IUMPR_TAP_FunPerf_Value: accessed-variable=VeCPDR_b_IUMPR_TAP_FunPerf.Value
              OUT_VeCPDR_b_IUMPR_TAP_MinCmdThrshld_Met_Value: accessed-variable=VeCPDR_b_IUMPR_TAP_MinCmdThrshld_Met.Value
              OUT_VeCPDR_e_FaultSts_AuxTransFldPmpPerf_Value: accessed-variable=VeCPDR_e_FaultSts_AuxTransFldPmpPerf.Value
          written-local-variables:
            16 x access:
              WV_AuxPumpSpdAct_AD_write_IRV: accessed-variable=AuxPumpSpdAct_AD_write_IRV, variation-point={short-label=vpWV_AuxPumpSpdAct_AD_write_IRV, sw-syscond=1}
              WV_BF1_SysVolt_AD_IRV: accessed-variable=BF1_SysVolt_AD_IRV, variation-point={short-label=vpWV_BF1_SysVolt_AD_IRV, sw-syscond=1}
              WV_BPCM_LIN_BusOff_AD_write_IRV: accessed-variable=BPCM_LIN_BusOff_AD_write_IRV, variation-point={short-label=vpWV_BPCM_LIN_BusOff_AD_write_IRV, sw-syscond=1}
              WV_BPCM_LIN_BusOff_FA_AD_write_IRV: accessed-variable=BPCM_LIN_BusOff_FA_AD_write_IRV, variation-point={short-label=vpWV_BPCM_LIN_BusOff_FA_AD_write_IRV, sw-syscond=1}
              WV_BPCM_LIN_BusOff_SgnlRcvd_AD_write_IRV: accessed-variable=BPCM_LIN_BusOff_SgnlRcvd_AD_write_IRV, variation-point={short-label=vpWV_BPCM_LIN_BusOff_SgnlRcvd_AD_write_IRV, sw-syscond=1}
              WV_BPCM_LOC_BCP_AD_write_IRV: accessed-variable=BPCM_LOC_BCP_AD_write_IRV, variation-point={short-label=vpWV_BPCM_LOC_BCP_AD_write_IRV, sw-syscond=1}
              WV_BPCM_LOC_BCP_FA_AD_write_IRV: accessed-variable=BPCM_LOC_BCP_FA_AD_write_IRV, variation-point={short-label=vpWV_BPCM_LOC_BCP_FA_AD_write_IRV, sw-syscond=1}
              WV_BPCM_LOC_BCP_SgnlRcvd_AD_write_IRV: accessed-variable=BPCM_LOC_BCP_SgnlRcvd_AD_write_IRV, variation-point={short-label=vpWV_BPCM_LOC_BCP_SgnlRcvd_AD_write_IRV, sw-syscond=1}
              WV_DsblDiagFailSafe_AD_write_IRV: accessed-variable=DsblDiagFailSafe_AD_write_IRV, variation-point={short-label=vpWV_DsblDiagFailSafe_AD_write_IRV, sw-syscond=1}
              WV_HTAP_MaxOpRPM_AD_write_IRV: accessed-variable=HTAP_MaxOpRPM_AD_write_IRV, variation-point={short-label=vpWV_HTAP_MaxOpRPM_AD_write_IRV, sw-syscond=1}
              WV_LTAP_MaxOpRPM_AD_write_IRV: accessed-variable=LTAP_MaxOpRPM_AD_write_IRV, variation-point={short-label=vpWV_LTAP_MaxOpRPM_AD_write_IRV, sw-syscond=1}
              WV_LTPP2_MaxOpRPM_AD_write_IRV: accessed-variable=LTPP2_MaxOpRPM_AD_write_IRV, variation-point={short-label=vpWV_LTPP2_MaxOpRPM_AD_write_IRV, sw-syscond=1}
              WV_LTPP_MaxOpRPM_AD_write_IRV: accessed-variable=LTPP_MaxOpRPM_AD_write_IRV, variation-point={short-label=vpWV_LTPP_MaxOpRPM_AD_write_IRV, sw-syscond=1}
              WV_PostCodeClrDiagDsbl_AD_write_IRV: accessed-variable=PostCodeClrDiagDsbl_AD_write_IRV, variation-point={short-label=vpWV_PostCodeClrDiagDsbl_AD_write_IRV, sw-syscond=1}
              WV_PropSysActv_AD_write_IRV: accessed-variable=PropSysActv_AD_write_IRV, variation-point={short-label=vpWV_PropSysActv_AD_write_IRV, sw-syscond=1}
              WV_TransAuxPmp_Cmd_AD_write_IRV: accessed-variable=TransAuxPmp_Cmd_AD_write_IRV, variation-point={short-label=vpWV_TransAuxPmp_Cmd_AD_write_IRV, sw-syscond=1}
        CPDR_MedTEH
          data-receive-point-by-arguments:
            80 x access:
              IN_VeDFIR_b_IsDiagGlobalConditionsValid_Value: accessed-variable=VeDFIR_b_IsDiagGlobalConditionsValid.Value, variation-point={short-label=vpIN_VeDFIR_b_IsDiagGlobalConditionsValid_Value, sw-syscond=1}
              IN_VeDMAB_y_StatusByte_BattCoolPmpOveSpd_Value: accessed-variable=VeDMAB_y_StatusByte_BattCoolPmpOveSpd.Value
              IN_VeDMAB_y_StatusByte_BattCoolPmpPerf_Value: accessed-variable=VeDMAB_y_StatusByte_BattCoolPmpPerf.Value
              IN_VeDMAB_y_StatusByte_CommBusOff_Value: accessed-variable=VeDMAB_y_StatusByte_CommBusOff.Value
              IN_VeDMAB_y_StatusByte_CommBus_B_Off_Value: accessed-variable=VeDMAB_y_StatusByte_CommBus_B_Off.Value
              IN_VeDMAB_y_StatusByte_CoolPmpACtrlCktPerf_Value: accessed-variable=VeDMAB_y_StatusByte_CoolPmpACtrlCktPerf.Value
              IN_VeDMAB_y_StatusByte_InvData_BECM_Value: accessed-variable=VeDMAB_y_StatusByte_InvData_BECM.Value
              IN_VeDMAB_y_StatusByte_InvData_BECM_CANC11_Value: accessed-variable=VeDMAB_y_StatusByte_InvData_BECM_CANC11.Value
              IN_VeDMAB_y_StatusByte_LIN{1..3}_BusOff_Value: accessed-variable=VeDMAB_y_StatusByte_LIN{1..3}_BusOff.Value
              IN_VeDMAB_y_StatusByte_LosCommBECM_A_Value: accessed-variable=VeDMAB_y_StatusByte_LosCommBECM_A.Value
              IN_VeDMAB_y_StatusByte_LosCommBECM_A_CANC11_Value: accessed-variable=VeDMAB_y_StatusByte_LosCommBECM_A_CANC11.Value
              IN_VeDMAB_y_StatusByte_LostCommCoolPmpA_Value: accessed-variable=VeDMAB_y_StatusByte_LostCommCoolPmpA.Value
              IN_VeDMAB_y_StatusByte_LostCommHB_CoolPmp_Value: accessed-variable=VeDMAB_y_StatusByte_LostCommHB_CoolPmp.Value
              IN_VeDMAB_y_StatusByte_LostCommMtrElectCoolPmpA_Value: accessed-variable=VeDMAB_y_StatusByte_LostCommMtrElectCoolPmpA.Value
              IN_VeDMAB_y_StatusByte_LostCommMtrElectCoolPmpB_Value: accessed-variable=VeDMAB_y_StatusByte_LostCommMtrElectCoolPmpB.Value
              IN_VeDMAB_y_StatusByte_LostCommPwrtrn_OilPmp1_Value: accessed-variable=VeDMAB_y_StatusByte_LostCommPwrtrn_OilPmp1.Value
              IN_VeDMAB_y_StatusByte_LostCommPwrtrn_OilPmp2_Value: accessed-variable=VeDMAB_y_StatusByte_LostCommPwrtrn_OilPmp2.Value
              IN_VeDMAB_y_StatusByte_MtrElect_CooPumBOvrSpd_Value: accessed-variable=VeDMAB_y_StatusByte_MtrElect_CooPumBOvrSpd.Value
              IN_VeDMAB_y_StatusByte_MtrElect_CoolPumAOvrSpd_Value: accessed-variable=VeDMAB_y_StatusByte_MtrElect_CoolPumAOvrSpd.Value
              IN_VeDMAB_y_StatusByte_MtrElect_CoolPumBCtrlPerf_Value: accessed-variable=VeDMAB_y_StatusByte_MtrElect_CoolPumBCtrlPerf.Value
              IN_VeDMAB_y_StatusByte_PwrElecPmpPerf_Value: accessed-variable=VeDMAB_y_StatusByte_PwrElecPmpPerf.Value
              IN_VeDMAB_y_StatusByte_PwrtrnOilPmp1OvrSpd_Value: accessed-variable=VeDMAB_y_StatusByte_PwrtrnOilPmp1OvrSpd.Value
              IN_VeDMAB_y_StatusByte_PwrtrnOilPmp1Perf_Value: accessed-variable=VeDMAB_y_StatusByte_PwrtrnOilPmp1Perf.Value
              IN_VeDMAB_y_StatusByte_PwrtrnOilPmp2OvrSpd_Value: accessed-variable=VeDMAB_y_StatusByte_PwrtrnOilPmp2OvrSpd.Value
              IN_VeDMAB_y_StatusByte_PwrtrnOilPmp2Perf_Value: accessed-variable=VeDMAB_y_StatusByte_PwrtrnOilPmp2Perf.Value
              IN_VeDMAB_y_StatusByte_ThrmlRlyCtrlCkt_Value: accessed-variable=VeDMAB_y_StatusByte_ThrmlRlyCtrlCkt.Value
              IN_VePMIR_T_HTAuxPumpTemp_Value: accessed-variable=VePMIR_T_HTAuxPumpTemp.Value, variation-point={short-label=vpIN_VePMIR_T_HTAuxPumpTemp_Value, sw-syscond=1}
              IN_VePMIR_T_LTActvPumpTemp_Value: accessed-variable=VePMIR_T_LTActvPumpTemp.Value, variation-point={short-label=vpIN_VePMIR_T_LTActvPumpTemp_Value, sw-syscond=1}
              IN_VePMIR_T_LTPsvPump2Temp_Value: accessed-variable=VePMIR_T_LTPsvPump2Temp.Value, variation-point={short-label=vpIN_VePMIR_T_LTPsvPump2Temp_Value, sw-syscond=1}
              IN_VePMIR_T_LTPsvPumpTemp_Value: accessed-variable=VePMIR_T_LTPsvPumpTemp.Value, variation-point={short-label=vpIN_VePMIR_T_LTPsvPumpTemp_Value, sw-syscond=1}
              IN_VePMIR_T_TransAuxPump2OilTemp_Value: accessed-variable=VePMIR_T_TransAuxPump2OilTemp.Value, variation-point={short-label=vpIN_VePMIR_T_TransAuxPump2OilTemp_Value, sw-syscond=1}
              IN_VePMIR_T_TransAuxPumpOilTemp_Value: accessed-variable=VePMIR_T_TransAuxPumpOilTemp.Value, variation-point={short-label=vpIN_VePMIR_T_TransAuxPumpOilTemp_Value, sw-syscond=1}
              IN_VePMIR_b_AuxPumpSpdAct_FA_Value: accessed-variable=VePMIR_b_AuxPumpSpdAct_FA.Value, variation-point={short-label=vpIN_VePMIR_b_AuxPumpSpdAct_FA_Value, sw-syscond=1}
              IN_VePMIR_b_AuxPumpSpdAct_SNA_Value: accessed-variable=VePMIR_b_AuxPumpSpdAct_SNA.Value, variation-point={short-label=vpIN_VePMIR_b_AuxPumpSpdAct_SNA_Value, sw-syscond=1}
              IN_VePMIR_b_HTAuxPumpRPMAct_SNA_Value: accessed-variable=VePMIR_b_HTAuxPumpRPMAct_SNA.Value, variation-point={short-label=vpIN_VePMIR_b_HTAuxPumpRPMAct_SNA_Value, sw-syscond=1}
              IN_VePMIR_b_HTAuxPumpTemp_FA_Value: accessed-variable=VePMIR_b_HTAuxPumpTemp_FA.Value, variation-point={short-label=vpIN_VePMIR_b_HTAuxPumpTemp_FA_Value, sw-syscond=1}
              IN_VePMIR_b_LTActvPumpDryRun_FA_Value: accessed-variable=VePMIR_b_LTActvPumpDryRun_FA.Value, variation-point={short-label=vpIN_VePMIR_b_LTActvPumpDryRun_FA_Value, sw-syscond=1}
              IN_VePMIR_b_LTActvPumpDryRun_SNA_Value: accessed-variable=VePMIR_b_LTActvPumpDryRun_SNA.Value, variation-point={short-label=vpIN_VePMIR_b_LTActvPumpDryRun_SNA_Value, sw-syscond=1}
              IN_VePMIR_b_LTActvPumpRPMAct_SNA_Value: accessed-variable=VePMIR_b_LTActvPumpRPMAct_SNA.Value, variation-point={short-label=vpIN_VePMIR_b_LTActvPumpRPMAct_SNA_Value, sw-syscond=1}
              IN_VePMIR_b_LTActvPumpTemp_FA_Value: accessed-variable=VePMIR_b_LTActvPumpTemp_FA.Value, variation-point={short-label=vpIN_VePMIR_b_LTActvPumpTemp_FA_Value, sw-syscond=1}
              IN_VePMIR_b_LTPsvPump2DryRun_FA_Value: accessed-variable=VePMIR_b_LTPsvPump2DryRun_FA.Value, variation-point={short-label=vpIN_VePMIR_b_LTPsvPump2DryRun_FA_Value, sw-syscond=1}
              IN_VePMIR_b_LTPsvPump2RPMAct_SNA_Value: accessed-variable=VePMIR_b_LTPsvPump2RPMAct_SNA.Value, variation-point={short-label=vpIN_VePMIR_b_LTPsvPump2RPMAct_SNA_Value, sw-syscond=1}
              IN_VePMIR_b_LTPsvPump2Temp_FA_Value: accessed-variable=VePMIR_b_LTPsvPump2Temp_FA.Value, variation-point={short-label=vpIN_VePMIR_b_LTPsvPump2Temp_FA_Value, sw-syscond=1}
              IN_VePMIR_b_LTPsvPumpDryRun_FA_Value: accessed-variable=VePMIR_b_LTPsvPumpDryRun_FA.Value, variation-point={short-label=vpIN_VePMIR_b_LTPsvPumpDryRun_FA_Value, sw-syscond=1}
              IN_VePMIR_b_LTPsvPumpTemp_FA_Value: accessed-variable=VePMIR_b_LTPsvPumpTemp_FA.Value, variation-point={short-label=vpIN_VePMIR_b_LTPsvPumpTemp_FA_Value, sw-syscond=1}
              IN_VePMIR_b_LTPsvPump_RPMAct_SNA_Value: accessed-variable=VePMIR_b_LTPsvPump_RPMAct_SNA.Value, variation-point={short-label=vpIN_VePMIR_b_LTPsvPump_RPMAct_SNA_Value, sw-syscond=1}
              IN_VePMIR_b_TransAuxPump2DryRun_FA_Value: accessed-variable=VePMIR_b_TransAuxPump2DryRun_FA.Value, variation-point={short-label=vpIN_VePMIR_b_TransAuxPump2DryRun_FA_Value, sw-syscond=1}
              IN_VePMIR_b_TransAuxPump2OilTemp_FA_Value: accessed-variable=VePMIR_b_TransAuxPump2OilTemp_FA.Value, variation-point={short-label=vpIN_VePMIR_b_TransAuxPump2OilTemp_FA_Value, sw-syscond=1}
              IN_VePMIR_b_TransAuxPump2SpdAct_FA_Value: accessed-variable=VePMIR_b_TransAuxPump2SpdAct_FA.Value, variation-point={short-label=vpIN_VePMIR_b_TransAuxPump2SpdAct_FA_Value, sw-syscond=1}
              IN_VePMIR_b_TransAuxPump2SpdAct_SNA_Value: accessed-variable=VePMIR_b_TransAuxPump2SpdAct_SNA.Value, variation-point={short-label=vpIN_VePMIR_b_TransAuxPump2SpdAct_SNA_Value, sw-syscond=1}
              IN_VePMIR_b_TransAuxPumpDryRun_FA_Value: accessed-variable=VePMIR_b_TransAuxPumpDryRun_FA.Value, variation-point={short-label=vpIN_VePMIR_b_TransAuxPumpDryRun_FA_Value, sw-syscond=1}
              IN_VePMIR_b_TransAuxPumpOilTemp_FA_Value: accessed-variable=VePMIR_b_TransAuxPumpOilTemp_FA.Value, variation-point={short-label=vpIN_VePMIR_b_TransAuxPumpOilTemp_FA_Value, sw-syscond=1}
              IN_VePMIR_e_HTAuxPumpDryRun_Value: accessed-variable=VePMIR_e_HTAuxPumpDryRun.Value, variation-point={short-label=vpIN_VePMIR_e_HTAuxPumpDryRun_Value, sw-syscond=1}
              IN_VePMIR_e_HTAuxPumpLmpHM_Value: accessed-variable=VePMIR_e_HTAuxPumpLmpHM.Value, variation-point={short-label=vpIN_VePMIR_e_HTAuxPumpLmpHM_Value, sw-syscond=1}
              IN_VePMIR_e_HTAuxPumpMntrRPM_Value: accessed-variable=VePMIR_e_HTAuxPumpMntrRPM.Value, variation-point={short-label=vpIN_VePMIR_e_HTAuxPumpMntrRPM_Value, sw-syscond=1}
              IN_VePMIR_e_LTActvPumpDryRun_Value: accessed-variable=VePMIR_e_LTActvPumpDryRun.Value, variation-point={short-label=vpIN_VePMIR_e_LTActvPumpDryRun_Value, sw-syscond=1}
              IN_VePMIR_e_LTActvPumpLmpHM_Value: accessed-variable=VePMIR_e_LTActvPumpLmpHM.Value, variation-point={short-label=vpIN_VePMIR_e_LTActvPumpLmpHM_Value, sw-syscond=1}
              IN_VePMIR_e_LTActvPumpMntrRPM_Value: accessed-variable=VePMIR_e_LTActvPumpMntrRPM.Value, variation-point={short-label=vpIN_VePMIR_e_LTActvPumpMntrRPM_Value, sw-syscond=1}
              IN_VePMIR_e_LTPsvPump2DryRun_Value: accessed-variable=VePMIR_e_LTPsvPump2DryRun.Value, variation-point={short-label=vpIN_VePMIR_e_LTPsvPump2DryRun_Value, sw-syscond=1}
              IN_VePMIR_e_LTPsvPump2LmpHM_Value: accessed-variable=VePMIR_e_LTPsvPump2LmpHM.Value, variation-point={short-label=vpIN_VePMIR_e_LTPsvPump2LmpHM_Value, sw-syscond=1}
              IN_VePMIR_e_LTPsvPump2MntrRPM_Value: accessed-variable=VePMIR_e_LTPsvPump2MntrRPM.Value, variation-point={short-label=vpIN_VePMIR_e_LTPsvPump2MntrRPM_Value, sw-syscond=1}
              IN_VePMIR_e_LTPsvPumpDryRun_Value: accessed-variable=VePMIR_e_LTPsvPumpDryRun.Value, variation-point={short-label=vpIN_VePMIR_e_LTPsvPumpDryRun_Value, sw-syscond=1}
              IN_VePMIR_e_LTPsvPumpLmpHM_Value: accessed-variable=VePMIR_e_LTPsvPumpLmpHM.Value, variation-point={short-label=vpIN_VePMIR_e_LTPsvPumpLmpHM_Value, sw-syscond=1}
              IN_VePMIR_e_LTPsvPumpMntrRPM_Value: accessed-variable=VePMIR_e_LTPsvPumpMntrRPM.Value, variation-point={short-label=vpIN_VePMIR_e_LTPsvPumpMntrRPM_Value, sw-syscond=1}
              IN_VePMIR_e_TransAuxPump2DryRun_Value: accessed-variable=VePMIR_e_TransAuxPump2DryRun.Value, variation-point={short-label=vpIN_VePMIR_e_TransAuxPump2DryRun_Value, sw-syscond=1}
              IN_VePMIR_e_TransAuxPumpDryRun_Value: accessed-variable=VePMIR_e_TransAuxPumpDryRun.Value, variation-point={short-label=vpIN_VePMIR_e_TransAuxPumpDryRun_Value, sw-syscond=1}
              IN_VePMIR_n_HTAuxPumpRPMAct_Value: accessed-variable=VePMIR_n_HTAuxPumpRPMAct.Value, variation-point={short-label=vpIN_VePMIR_n_HTAuxPumpRPMAct_Value, sw-syscond=1}
              IN_VePMIR_n_LTActvPumpRPMAct_Value: accessed-variable=VePMIR_n_LTActvPumpRPMAct.Value, variation-point={short-label=vpIN_VePMIR_n_LTActvPumpRPMAct_Value, sw-syscond=1}
              IN_VePMIR_n_LTPsvPump2RPMAct_Value: accessed-variable=VePMIR_n_LTPsvPump2RPMAct.Value, variation-point={short-label=vpIN_VePMIR_n_LTPsvPump2RPMAct_Value, sw-syscond=1}
              IN_VePMIR_n_LTPsvPump_RPMAct_Value: accessed-variable=VePMIR_n_LTPsvPump_RPMAct.Value, variation-point={short-label=vpIN_VePMIR_n_LTPsvPump_RPMAct_Value, sw-syscond=1}
              IN_VePMIR_n_TransAuxPump2SpdAct_Value: accessed-variable=VePMIR_n_TransAuxPump2SpdAct.Value, variation-point={short-label=vpIN_VePMIR_n_TransAuxPump2SpdAct_Value, sw-syscond=1}
              IN_VePMPR_n_HT_AuxPmpCmd_Value: accessed-variable=VePMPR_n_HT_AuxPmpCmd.Value, variation-point={short-label=vpIN_VePMPR_n_HT_AuxPmpCmd_Value, sw-syscond=1}
              IN_VePMPR_n_LT_ActvPmpCmd_Value: accessed-variable=VePMPR_n_LT_ActvPmpCmd.Value, variation-point={short-label=vpIN_VePMPR_n_LT_ActvPmpCmd_Value, sw-syscond=1}
              IN_VePMPR_n_LT_PsvPmp2Cmd_Value: accessed-variable=VePMPR_n_LT_PsvPmp2Cmd.Value, variation-point={short-label=vpIN_VePMPR_n_LT_PsvPmp2Cmd_Value, sw-syscond=1}
              IN_VePMPR_n_LT_PsvPmpCmd_Value: accessed-variable=VePMPR_n_LT_PsvPmpCmd.Value, variation-point={short-label=vpIN_VePMPR_n_LT_PsvPmpCmd_Value, sw-syscond=1}
              IN_VePMTR_e_ThrmlDevEnbl_Value: accessed-variable=VePMTR_e_ThrmlDevEnbl.Value, variation-point={short-label=vpIN_VePMTR_e_ThrmlDevEnbl_Value, sw-syscond=1}
              IN_VeTAPR_n_TransAuxPmp2_Cmd_Value: accessed-variable=VeTAPR_n_TransAuxPmp2_Cmd.Value, variation-point={short-label=vpIN_VeTAPR_n_TransAuxPmp2_Cmd_Value, sw-syscond=1}
              IN_VeTMIR_b_MainRly_CmdReq_Value: accessed-variable=VeTMIR_b_MainRly_CmdReq.Value, variation-point={short-label=vpIN_VeTMIR_b_MainRly_CmdReq_Value, sw-syscond=1}
          data-send-points:
            41 x access:
              OUT_VeCPDR_e_FaultSts_PwrElecPmpPerf_Value: accessed-variable=VeCPDR_e_FaultSts_PwrElecPmpPerf.Value
              OUT_VeCPDR_b_LTPP_FunPer_FltDtct_Value: accessed-variable=VeCPDR_b_LTPP_FunPer_FltDtct.Value
              OUT_VeCPDR_e_FaultSts_MtrElect_CoolPumAOvrSpd_Value: accessed-variable=VeCPDR_e_FaultSts_MtrElect_CoolPumAOvrSpd.Value
              OUT_VeCPDR_b_IUMPR_PECP_MinCmdThrshld_Met_Value: accessed-variable=VeCPDR_b_IUMPR_PECP_MinCmdThrshld_Met.Value
              OUT_VeCPDR_e_FaultSts_MtrElect_CoolPumBCtrlPerf_Value: accessed-variable=VeCPDR_e_FaultSts_MtrElect_CoolPumBCtrlPerf.Value
              OUT_VeCPDR_b_LTPP2_FunPer_FltDtct_Value: accessed-variable=VeCPDR_b_LTPP2_FunPer_FltDtct.Value
              OUT_VeCPDR_e_FaultSts_MtrElect_CooPumBOvrSpd_Value: accessed-variable=VeCPDR_e_FaultSts_MtrElect_CooPumBOvrSpd.Value
              OUT_VeCPDR_b_IUMPR_PECP2_MinCmdThrshld_Met_Value: accessed-variable=VeCPDR_b_IUMPR_PECP2_MinCmdThrshld_Met.Value
              OUT_VeCPDR_b_LTCL_FunPer_FltDtct_Value: accessed-variable=VeCPDR_b_LTCL_FunPer_FltDtct.Value
              OUT_VeCPDR_b_LTCL_DryRun_FltDtct_Value: accessed-variable=VeCPDR_b_LTCL_DryRun_FltDtct.Value
              OUT_VeCPDR_e_FaultSts_BattCoolPmpPerf_Value: accessed-variable=VeCPDR_e_FaultSts_BattCoolPmpPerf.Value
              OUT_VeCPDR_b_LTAP_FunPer_FltDtct_Value: accessed-variable=VeCPDR_b_LTAP_FunPer_FltDtct.Value
              OUT_VeCPDR_e_FaultSts_BattCoolPmpOveSpd_Value: accessed-variable=VeCPDR_e_FaultSts_BattCoolPmpOveSpd.Value
              OUT_VeCPDR_b_IUMPR_LTAP_MinCmdThrshld_Met_Value: accessed-variable=VeCPDR_b_IUMPR_LTAP_MinCmdThrshld_Met.Value
              OUT_VeCPDR_b_IUMPR_LTAP_DryRun_Value: accessed-variable=VeCPDR_b_IUMPR_LTAP_DryRun.Value
              OUT_VeCPDR_e_FaultSts_CoolPmpACtrlCktPerf_Value: accessed-variable=VeCPDR_e_FaultSts_CoolPmpACtrlCktPerf.Value
              OUT_VeCPDR_b_HTAP_FunPer_FltDtct_Value: accessed-variable=VeCPDR_b_HTAP_FunPer_FltDtct.Value
              OUT_VeCPDR_b_IUMPR_HTAP_MinCmdThrshld_Met_Value: accessed-variable=VeCPDR_b_IUMPR_HTAP_MinCmdThrshld_Met.Value
              OUT_VeCPDR_e_FaultSts_PwrtrnOilPmp1Perf_Value: accessed-variable=VeCPDR_e_FaultSts_PwrtrnOilPmp1Perf.Value
              OUT_VeCPDR_e_FaultSts_PwrtrnOilPmp1OvrSpd_Value: accessed-variable=VeCPDR_e_FaultSts_PwrtrnOilPmp1OvrSpd.Value
              OUT_VeCPDR_b_IUMPR_EOPA_MinCmdThrshld_Met_Value: accessed-variable=VeCPDR_b_IUMPR_EOPA_MinCmdThrshld_Met.Value
              OUT_VeCPDR_b_IUMPR_EOPA_FunPerf_Value: accessed-variable=VeCPDR_b_IUMPR_EOPA_FunPerf.Value
              OUT_VeCPDR_b_IUMPR_EOPA_DryRun_Value: accessed-variable=VeCPDR_b_IUMPR_EOPA_DryRun.Value
              OUT_VeCPDR_e_FaultSts_PwrtrnOilPmp2Perf_Value: accessed-variable=VeCPDR_e_FaultSts_PwrtrnOilPmp2Perf.Value
              OUT_VeCPDR_e_FaultSts_PwrtrnOilPmp2OvrSpd_Value: accessed-variable=VeCPDR_e_FaultSts_PwrtrnOilPmp2OvrSpd.Value
              OUT_VeCPDR_b_IUMPR_EOPB_MinCmdThrshld_Met_Value: accessed-variable=VeCPDR_b_IUMPR_EOPB_MinCmdThrshld_Met.Value
              OUT_VeCPDR_b_IUMPR_EOPB_FunPerf_Value: accessed-variable=VeCPDR_b_IUMPR_EOPB_FunPerf.Value
              OUT_VeCPDR_b_IUMPR_EOPB_DryRun_Value: accessed-variable=VeCPDR_b_IUMPR_EOPB_DryRun.Value
              OUT_VeCPDR_e_FaultSts_Aux_TF_Pmp_CM_Fdbck_SigRan_Value: accessed-variable=VeCPDR_e_FaultSts_Aux_TF_Pmp_CM_Fdbck_SigRan.Value
              OUT_VeCPDR_b_IUMPR_PWM_EOP_MinCmdThrshld_Met_Value: accessed-variable=VeCPDR_b_IUMPR_PWM_EOP_MinCmdThrshld_Met.Value
              OUT_VeCPDR_b_IUMPR_PWM_EOP_FunPerf_Value: accessed-variable=VeCPDR_b_IUMPR_PWM_EOP_FunPerf.Value
              OUT_VeCPDR_b_LTPP_FunPer_ChkEnbl_Value: accessed-variable=VeCPDR_b_LTPP_FunPer_ChkEnbl.Value
              OUT_VeCPDR_b_LTPP2_FunPer_ChkEnbl_Value: accessed-variable=VeCPDR_b_LTPP2_FunPer_ChkEnbl.Value
              OUT_VeCPDR_b_LTAP_FunPer_ChkEnbl_Value: accessed-variable=VeCPDR_b_LTAP_FunPer_ChkEnbl.Value
              OUT_VeCPDR_b_HTAP_FunPer_ChkEnbl_Value: accessed-variable=VeCPDR_b_HTAP_FunPer_ChkEnbl.Value
              OUT_VeCPDR_b_IUMPR_PECP_FunPerf_Value: accessed-variable=VeCPDR_b_IUMPR_PECP_FunPerf.Value
              OUT_VeCPDR_b_IUMPR_LTPP_DryRun_Value: accessed-variable=VeCPDR_b_IUMPR_LTPP_DryRun.Value
              OUT_VeCPDR_b_IUMPR_PECP2_FunPerf_Value: accessed-variable=VeCPDR_b_IUMPR_PECP2_FunPerf.Value
              OUT_VeCPDR_b_IUMPR_LTPP2_DryRun_Value: accessed-variable=VeCPDR_b_IUMPR_LTPP2_DryRun.Value
              OUT_VeCPDR_b_IUMPR_LTAP_FunPerf_Value: accessed-variable=VeCPDR_b_IUMPR_LTAP_FunPerf.Value
              OUT_VeCPDR_b_IUMPR_HTAP_FunPerf_Value: accessed-variable=VeCPDR_b_IUMPR_HTAP_FunPerf.Value
          read-local-variables:
            10 x access:
              RV_AuxPumpSpdAct_AD_write_IRV: accessed-variable=AuxPumpSpdAct_AD_write_IRV, variation-point={short-label=vpRV_AuxPumpSpdAct_AD_write_IRV, sw-syscond=1}
              RV_BF1_SysVolt_AD_IRV: accessed-variable=BF1_SysVolt_AD_IRV, variation-point={short-label=vpRV_BF1_SysVolt_AD_IRV, sw-syscond=1}
              RV_DsblDiagFailSafe_AD_write_IRV: accessed-variable=DsblDiagFailSafe_AD_write_IRV, variation-point={short-label=vpRV_DsblDiagFailSafe_AD_write_IRV, sw-syscond=1}
              RV_HTAP_MaxOpRPM_AD_write_IRV: accessed-variable=HTAP_MaxOpRPM_AD_write_IRV, variation-point={short-label=vpRV_HTAP_MaxOpRPM_AD_write_IRV, sw-syscond=1}
              RV_LTAP_MaxOpRPM_AD_write_IRV: accessed-variable=LTAP_MaxOpRPM_AD_write_IRV, variation-point={short-label=vpRV_LTAP_MaxOpRPM_AD_write_IRV, sw-syscond=1}
              RV_LTPP2_MaxOpRPM_AD_write_IRV: accessed-variable=LTPP2_MaxOpRPM_AD_write_IRV, variation-point={short-label=vpRV_LTPP2_MaxOpRPM_AD_write_IRV, sw-syscond=1}
              RV_LTPP_MaxOpRPM_AD_write_IRV: accessed-variable=LTPP_MaxOpRPM_AD_write_IRV, variation-point={short-label=vpRV_LTPP_MaxOpRPM_AD_write_IRV, sw-syscond=1}
              RV_PostCodeClrDiagDsbl_AD_write_IRV: accessed-variable=PostCodeClrDiagDsbl_AD_write_IRV, variation-point={short-label=vpRV_PostCodeClrDiagDsbl_AD_write_IRV, sw-syscond=1}
              RV_PropSysActv_AD_write_IRV: accessed-variable=PropSysActv_AD_write_IRV, variation-point={short-label=vpRV_PropSysActv_AD_write_IRV, sw-syscond=1}
              RV_TransAuxPmp_Cmd_AD_write_IRV: accessed-variable=TransAuxPmp_Cmd_AD_write_IRV, variation-point={short-label=vpRV_TransAuxPmp_Cmd_AD_write_IRV, sw-syscond=1}
        CPDR_PwrOn
          data-receive-point-by-arguments:
            11 x access:
              IN_NeCPDR_Cnt_EOPA_FunDryRun_MFOP_Rx_NeCPDR_Cnt_EOPA_FunDryRun_MFOP: accessed-variable=NeCPDR_Cnt_EOPA_FunDryRun_MFOP_Rx.NeCPDR_Cnt_EOPA_FunDryRun_MFOP
              IN_NeCPDR_Cnt_EOPA_FunPer_MFOP_Rx_NeCPDR_Cnt_EOPA_FunPer_MFOP: accessed-variable=NeCPDR_Cnt_EOPA_FunPer_MFOP_Rx.NeCPDR_Cnt_EOPA_FunPer_MFOP
              IN_NeCPDR_Cnt_EOPB_FunDryRun_MFOP_Rx_NeCPDR_Cnt_EOPB_FunDryRun_MFOP: accessed-variable=NeCPDR_Cnt_EOPB_FunDryRun_MFOP_Rx.NeCPDR_Cnt_EOPB_FunDryRun_MFOP
              IN_NeCPDR_Cnt_EOPB_FunPer_MFOP_Rx_NeCPDR_Cnt_EOPB_FunPer_MFOP: accessed-variable=NeCPDR_Cnt_EOPB_FunPer_MFOP_Rx.NeCPDR_Cnt_EOPB_FunPer_MFOP
              IN_NeCPDR_Cnt_HTAP_FunPer_MFOP_Rx_NeCPDR_Cnt_HTAP_FunPer_MFOP: accessed-variable=NeCPDR_Cnt_HTAP_FunPer_MFOP_Rx.NeCPDR_Cnt_HTAP_FunPer_MFOP
              IN_NeCPDR_Cnt_LTAP_FunDryRun_MFOP_Rx_NeCPDR_Cnt_LTAP_FunDryRun_MFOP: accessed-variable=NeCPDR_Cnt_LTAP_FunDryRun_MFOP_Rx.NeCPDR_Cnt_LTAP_FunDryRun_MFOP
              IN_NeCPDR_Cnt_LTAP_FunPer_MFOP_Rx_NeCPDR_Cnt_LTAP_FunPer_MFOP: accessed-variable=NeCPDR_Cnt_LTAP_FunPer_MFOP_Rx.NeCPDR_Cnt_LTAP_FunPer_MFOP
              IN_NeCPDR_Cnt_LTPP2_FunDryRun_MFOP_Rx_NeCPDR_Cnt_LTPP2_FunDryRun_MFOP: accessed-variable=NeCPDR_Cnt_LTPP2_FunDryRun_MFOP_Rx.NeCPDR_Cnt_LTPP2_FunDryRun_MFOP
              IN_NeCPDR_Cnt_LTPP2_FunPer_MFOP_Rx_NeCPDR_Cnt_LTPP2_FunPer_MFOP: accessed-variable=NeCPDR_Cnt_LTPP2_FunPer_MFOP_Rx.NeCPDR_Cnt_LTPP2_FunPer_MFOP
              IN_NeCPDR_Cnt_LTPP_FunDryRun_MFOP_Rx_NeCPDR_Cnt_LTPP_FunDryRun_MFOP: accessed-variable=NeCPDR_Cnt_LTPP_FunDryRun_MFOP_Rx.NeCPDR_Cnt_LTPP_FunDryRun_MFOP
              IN_NeCPDR_Cnt_LTPP_FunPer_MFOP_Rx_NeCPDR_Cnt_LTPP_FunPer_MFOP: accessed-variable=NeCPDR_Cnt_LTPP_FunPer_MFOP_Rx.NeCPDR_Cnt_LTPP_FunPer_MFOP
          data-send-points:
            45 x access:
              OUT_VeCPDR_b_LTPP_FunPer_ChkEnbl_Value: accessed-variable=VeCPDR_b_LTPP_FunPer_ChkEnbl.Value
              OUT_VeCPDR_b_LTPP_FunPer_FltDtct_Value: accessed-variable=VeCPDR_b_LTPP_FunPer_FltDtct.Value
              OUT_VeCPDR_b_LTPP2_FunPer_ChkEnbl_Value: accessed-variable=VeCPDR_b_LTPP2_FunPer_ChkEnbl.Value
              OUT_VeCPDR_b_LTPP2_FunPer_FltDtct_Value: accessed-variable=VeCPDR_b_LTPP2_FunPer_FltDtct.Value
              OUT_VeCPDR_b_LTAP_FunPer_ChkEnbl_Value: accessed-variable=VeCPDR_b_LTAP_FunPer_ChkEnbl.Value
              OUT_VeCPDR_b_LTAP_FunPer_FltDtct_Value: accessed-variable=VeCPDR_b_LTAP_FunPer_FltDtct.Value
              OUT_VeCPDR_b_HTAP_FunPer_ChkEnbl_Value: accessed-variable=VeCPDR_b_HTAP_FunPer_ChkEnbl.Value
              OUT_VeCPDR_b_HTAP_FunPer_FltDtct_Value: accessed-variable=VeCPDR_b_HTAP_FunPer_FltDtct.Value
              OUT_VeCPDR_b_IUMPR_PECP_FunPerf_Value: accessed-variable=VeCPDR_b_IUMPR_PECP_FunPerf.Value
              OUT_VeCPDR_b_IUMPR_LTPP_DryRun_Value: accessed-variable=VeCPDR_b_IUMPR_LTPP_DryRun.Value
              OUT_VeCPDR_b_IUMPR_PECP2_FunPerf_Value: accessed-variable=VeCPDR_b_IUMPR_PECP2_FunPerf.Value
              OUT_VeCPDR_b_IUMPR_LTPP2_DryRun_Value: accessed-variable=VeCPDR_b_IUMPR_LTPP2_DryRun.Value
              OUT_VeCPDR_b_IUMPR_LTAP_FunPerf_Value: accessed-variable=VeCPDR_b_IUMPR_LTAP_FunPerf.Value
              OUT_VeCPDR_b_IUMPR_HTAP_FunPerf_Value: accessed-variable=VeCPDR_b_IUMPR_HTAP_FunPerf.Value
              OUT_VeCPDR_b_IUMPR_PECP_MinCmdThrshld_Met_Value: accessed-variable=VeCPDR_b_IUMPR_PECP_MinCmdThrshld_Met.Value
              OUT_VeCPDR_b_LTCL_FunPer_FltDtct_Value: accessed-variable=VeCPDR_b_LTCL_FunPer_FltDtct.Value
              OUT_VeCPDR_b_LTCL_DryRun_FltDtct_Value: accessed-variable=VeCPDR_b_LTCL_DryRun_FltDtct.Value
              OUT_VeCPDR_b_IUMPR_PECP2_MinCmdThrshld_Met_Value: accessed-variable=VeCPDR_b_IUMPR_PECP2_MinCmdThrshld_Met.Value
              OUT_VeCPDR_b_IUMPR_LTAP_MinCmdThrshld_Met_Value: accessed-variable=VeCPDR_b_IUMPR_LTAP_MinCmdThrshld_Met.Value
              OUT_VeCPDR_b_IUMPR_HTAP_MinCmdThrshld_Met_Value: accessed-variable=VeCPDR_b_IUMPR_HTAP_MinCmdThrshld_Met.Value
              OUT_VeCPDR_b_IUMPR_LTAP_DryRun_Value: accessed-variable=VeCPDR_b_IUMPR_LTAP_DryRun.Value
              OUT_VeCPDR_b_IUMPR_EOPA_MinCmdThrshld_Met_Value: accessed-variable=VeCPDR_b_IUMPR_EOPA_MinCmdThrshld_Met.Value
              OUT_VeCPDR_b_IUMPR_EOPA_FunPerf_Value: accessed-variable=VeCPDR_b_IUMPR_EOPA_FunPerf.Value
              OUT_VeCPDR_b_IUMPR_EOPA_DryRun_Value: accessed-variable=VeCPDR_b_IUMPR_EOPA_DryRun.Value
              OUT_VeCPDR_b_IUMPR_EOPB_MinCmdThrshld_Met_Value: accessed-variable=VeCPDR_b_IUMPR_EOPB_MinCmdThrshld_Met.Value
              OUT_VeCPDR_b_IUMPR_EOPB_FunPerf_Value: accessed-variable=VeCPDR_b_IUMPR_EOPB_FunPerf.Value
              OUT_VeCPDR_b_IUMPR_EOPB_DryRun_Value: accessed-variable=VeCPDR_b_IUMPR_EOPB_DryRun.Value
              OUT_VeCPDR_b_AuxPumpPerf_FltDtct_Value: accessed-variable=VeCPDR_b_AuxPumpPerf_FltDtct.Value
              OUT_VeCPDR_b_IUMPR_TAP_FunPerf_Value: accessed-variable=VeCPDR_b_IUMPR_TAP_FunPerf.Value
              OUT_VeCPDR_b_IUMPR_TAP_MinCmdThrshld_Met_Value: accessed-variable=VeCPDR_b_IUMPR_TAP_MinCmdThrshld_Met.Value
              OUT_VeCPDR_b_IUMPR_PWM_EOP_MinCmdThrshld_Met_Value: accessed-variable=VeCPDR_b_IUMPR_PWM_EOP_MinCmdThrshld_Met.Value
              OUT_VeCPDR_b_IUMPR_PWM_EOP_FunPerf_Value: accessed-variable=VeCPDR_b_IUMPR_PWM_EOP_FunPerf.Value
              OUT_VeCPDR_e_FaultSts_AuxTransFldPmpPerf_Value: accessed-variable=VeCPDR_e_FaultSts_AuxTransFldPmpPerf.Value
              OUT_VeCPDR_e_FaultSts_BattCoolPmpOveSpd_Value: accessed-variable=VeCPDR_e_FaultSts_BattCoolPmpOveSpd.Value
              OUT_VeCPDR_e_FaultSts_BattCoolPmpPerf_Value: accessed-variable=VeCPDR_e_FaultSts_BattCoolPmpPerf.Value
              OUT_VeCPDR_e_FaultSts_PwrtrnOilPmp1OvrSpd_Value: accessed-variable=VeCPDR_e_FaultSts_PwrtrnOilPmp1OvrSpd.Value
              OUT_VeCPDR_e_FaultSts_PwrtrnOilPmp1Perf_Value: accessed-variable=VeCPDR_e_FaultSts_PwrtrnOilPmp1Perf.Value
              OUT_VeCPDR_e_FaultSts_PwrtrnOilPmp2OvrSpd_Value: accessed-variable=VeCPDR_e_FaultSts_PwrtrnOilPmp2OvrSpd.Value
              OUT_VeCPDR_e_FaultSts_PwrtrnOilPmp2Perf_Value: accessed-variable=VeCPDR_e_FaultSts_PwrtrnOilPmp2Perf.Value
              OUT_VeCPDR_e_FaultSts_CoolPmpACtrlCktPerf_Value: accessed-variable=VeCPDR_e_FaultSts_CoolPmpACtrlCktPerf.Value
              OUT_VeCPDR_e_FaultSts_MtrElect_CooPumBOvrSpd_Value: accessed-variable=VeCPDR_e_FaultSts_MtrElect_CooPumBOvrSpd.Value
              OUT_VeCPDR_e_FaultSts_MtrElect_CoolPumBCtrlPerf_Value: accessed-variable=VeCPDR_e_FaultSts_MtrElect_CoolPumBCtrlPerf.Value
              OUT_VeCPDR_e_FaultSts_MtrElect_CoolPumAOvrSpd_Value: accessed-variable=VeCPDR_e_FaultSts_MtrElect_CoolPumAOvrSpd.Value
              OUT_VeCPDR_e_FaultSts_PwrElecPmpPerf_Value: accessed-variable=VeCPDR_e_FaultSts_PwrElecPmpPerf.Value
              OUT_VeCPDR_e_FaultSts_Aux_TF_Pmp_CM_Fdbck_SigRan_Value: accessed-variable=VeCPDR_e_FaultSts_Aux_TF_Pmp_CM_Fdbck_SigRan.Value
          written-local-variables:
            16 x access:
              WV_AuxPumpSpdAct_AD_write_IRV: accessed-variable=AuxPumpSpdAct_AD_write_IRV
              WV_BF1_SysVolt_AD_IRV: accessed-variable=BF1_SysVolt_AD_IRV
              WV_BPCM_LIN_BusOff_AD_write_IRV: accessed-variable=BPCM_LIN_BusOff_AD_write_IRV
              WV_BPCM_LIN_BusOff_FA_AD_write_IRV: accessed-variable=BPCM_LIN_BusOff_FA_AD_write_IRV
              WV_BPCM_LIN_BusOff_SgnlRcvd_AD_write_IRV: accessed-variable=BPCM_LIN_BusOff_SgnlRcvd_AD_write_IRV
              WV_BPCM_LOC_BCP_AD_write_IRV: accessed-variable=BPCM_LOC_BCP_AD_write_IRV
              WV_BPCM_LOC_BCP_FA_AD_write_IRV: accessed-variable=BPCM_LOC_BCP_FA_AD_write_IRV
              WV_BPCM_LOC_BCP_SgnlRcvd_AD_write_IRV: accessed-variable=BPCM_LOC_BCP_SgnlRcvd_AD_write_IRV
              WV_DsblDiagFailSafe_AD_write_IRV: accessed-variable=DsblDiagFailSafe_AD_write_IRV
              WV_HTAP_MaxOpRPM_AD_write_IRV: accessed-variable=HTAP_MaxOpRPM_AD_write_IRV
              WV_LTAP_MaxOpRPM_AD_write_IRV: accessed-variable=LTAP_MaxOpRPM_AD_write_IRV
              WV_LTPP2_MaxOpRPM_AD_write_IRV: accessed-variable=LTPP2_MaxOpRPM_AD_write_IRV
              WV_LTPP_MaxOpRPM_AD_write_IRV: accessed-variable=LTPP_MaxOpRPM_AD_write_IRV
              WV_PostCodeClrDiagDsbl_AD_write_IRV: accessed-variable=PostCodeClrDiagDsbl_AD_write_IRV
              WV_PropSysActv_AD_write_IRV: accessed-variable=PropSysActv_AD_write_IRV
              WV_TransAuxPmp_Cmd_AD_write_IRV: accessed-variable=TransAuxPmp_Cmd_AD_write_IRV
        CPDR_PwrOff
          data-send-points:
            11 x access:
              OUT_NeCPDR_Cnt_EOPA_FunDryRun_MFOP_NeCPDR_Cnt_EOPA_FunDryRun_MFOP: accessed-variable=NeCPDR_Cnt_EOPA_FunDryRun_MFOP.NeCPDR_Cnt_EOPA_FunDryRun_MFOP
              OUT_NeCPDR_Cnt_EOPA_FunPer_MFOP_NeCPDR_Cnt_EOPA_FunPer_MFOP: accessed-variable=NeCPDR_Cnt_EOPA_FunPer_MFOP.NeCPDR_Cnt_EOPA_FunPer_MFOP
              OUT_NeCPDR_Cnt_EOPB_FunDryRun_MFOP_NeCPDR_Cnt_EOPB_FunDryRun_MFOP: accessed-variable=NeCPDR_Cnt_EOPB_FunDryRun_MFOP.NeCPDR_Cnt_EOPB_FunDryRun_MFOP
              OUT_NeCPDR_Cnt_EOPB_FunPer_MFOP_NeCPDR_Cnt_EOPB_FunPer_MFOP: accessed-variable=NeCPDR_Cnt_EOPB_FunPer_MFOP.NeCPDR_Cnt_EOPB_FunPer_MFOP
              OUT_NeCPDR_Cnt_HTAP_FunPer_MFOP_NeCPDR_Cnt_HTAP_FunPer_MFOP: accessed-variable=NeCPDR_Cnt_HTAP_FunPer_MFOP.NeCPDR_Cnt_HTAP_FunPer_MFOP
              OUT_NeCPDR_Cnt_LTAP_FunDryRun_MFOP_NeCPDR_Cnt_LTAP_FunDryRun_MFOP: accessed-variable=NeCPDR_Cnt_LTAP_FunDryRun_MFOP.NeCPDR_Cnt_LTAP_FunDryRun_MFOP
              OUT_NeCPDR_Cnt_LTAP_FunPer_MFOP_NeCPDR_Cnt_LTAP_FunPer_MFOP: accessed-variable=NeCPDR_Cnt_LTAP_FunPer_MFOP.NeCPDR_Cnt_LTAP_FunPer_MFOP
              OUT_NeCPDR_Cnt_LTPP2_FunDryRun_MFOP_NeCPDR_Cnt_LTPP2_FunDryRun_MFOP: accessed-variable=NeCPDR_Cnt_LTPP2_FunDryRun_MFOP.NeCPDR_Cnt_LTPP2_FunDryRun_MFOP
              OUT_NeCPDR_Cnt_LTPP2_FunPer_MFOP_NeCPDR_Cnt_LTPP2_FunPer_MFOP: accessed-variable=NeCPDR_Cnt_LTPP2_FunPer_MFOP.NeCPDR_Cnt_LTPP2_FunPer_MFOP
              OUT_NeCPDR_Cnt_LTPP_FunDryRun_MFOP_NeCPDR_Cnt_LTPP_FunDryRun_MFOP: accessed-variable=NeCPDR_Cnt_LTPP_FunDryRun_MFOP.NeCPDR_Cnt_LTPP_FunDryRun_MFOP
              OUT_NeCPDR_Cnt_LTPP_FunPer_MFOP_NeCPDR_Cnt_LTPP_FunPer_MFOP: accessed-variable=NeCPDR_Cnt_LTPP_FunPer_MFOP.NeCPDR_Cnt_LTPP_FunPer_MFOP
      11 x variation point proxy, all with category=CONDITION:
        Variant_CPDR_1: condition-access=1
        Variant_CPDR_10: condition-access=0
        Variant_CPDR_11: condition-access=0
        Variant_CPDR_2: condition-access=0
        Variant_CPDR_{3..9}: condition-access=1
